AUTOSAR XML (schema 4-3-0)
package /MICROSAR/NvM_swc/DataTypes
  impl type NvM_RequestResultType: compu {0=NVM_REQ_OK, 1=NVM_REQ_NOT_OK, 2=NVM_REQ_PENDING, 3=NVM_REQ_INTEGRITY_FAILED, 4=NVM_REQ_BLOCK_SKIPPED, 5=NVM_REQ_NV_INVALIDATED, 6=NVM_REQ_CANCELED, 7=NVM_REQ_REDUNDANCY_FAILED, 8=NVM_REQ_RESTORED_FROM_ROM}, implementation-data-type=uint8
  impl type NvM_BlockIdType: range raw 1..32767, implementation-data-type=uint16
  impl type NvM_ServiceIdType: compu {6=NVM_READ_BLOCK, 7=NVM_WRITE_BLOCK, 8=NVM_RESTORE_BLOCK_DEFAULTS, 9=NVM_ERASE_BLOCK, 11=NVM_INVALIDATE_NV_BLOCK, 12=NVM_READ_ALL}, implementation-data-type=uint8
package /MICROSAR/NvM_swc/Interfaces
  6 x client server interface, all with is-service=true, service-kind=NON-VOLATILE-RAM-MANAGER:
    NvMAdministration
      operation SetBlockProtection: possible-error=NvMAdministration/E_NOT_OK
        arg ProtectionEnabled: type=boolean, direction=IN
      error E_NOT_OK: error-code=1
    NvMService_AC3_SRBS
      6 x operation, all with possible-error=NvMService_AC3_SRBS/E_NOT_OK:
        GetErrorStatus
          arg ErrorStatus: type=NvM_RequestResultType, direction=OUT
        SetRamBlockStatus
          arg RamBlockStatus: type=boolean, direction=IN
        ReadBlock
          arg DstPtr: type=dtRef_VOID, direction=IN
        WriteBlock
          arg SrcPtr: type=dtRef_const_VOID, direction=IN
        InvalidateNvBlock
        EraseBlock
      error E_NOT_OK: error-code=1
    NvMService_AC3_SRBS_Defs
      7 x operation, all with possible-error=NvMService_AC3_SRBS_Defs/E_NOT_OK:
        GetErrorStatus
          arg ErrorStatus: type=NvM_RequestResultType, direction=OUT
        SetRamBlockStatus
          arg RamBlockStatus: type=boolean, direction=IN
        ReadBlock
          arg DstPtr: type=dtRef_VOID, direction=IN
        WriteBlock
          arg SrcPtr: type=dtRef_const_VOID, direction=IN
        RestoreBlockDefaults
          arg DstPtr: type=dtRef_VOID, direction=IN
        InvalidateNvBlock
        EraseBlock
      error E_NOT_OK: error-code=1
    NvMNotifyJobFinished
      operation JobFinished
        arg ServiceId: type=NvM_ServiceIdType, direction=IN
        arg JobResult: type=NvM_RequestResultType, direction=IN
    NvMNotifyInitBlock
      operation InitBlock
    NvMService_AC3_SRBS_DS
      8 x operation, all with possible-error=NvMService_AC3_SRBS_DS/E_NOT_OK:
        GetErrorStatus
          arg ErrorStatus: type=NvM_RequestResultType, direction=OUT
        SetRamBlockStatus
          arg RamBlockStatus: type=boolean, direction=IN
        ReadBlock
          arg DstPtr: type=dtRef_VOID, direction=IN
        WriteBlock
          arg SrcPtr: type=dtRef_const_VOID, direction=IN
        SetDataIndex
          arg DataIndex: type=uint8, direction=IN
        GetDataIndex
          arg DataIndex: type=uint8, direction=OUT
        InvalidateNvBlock
        EraseBlock
      error E_NOT_OK: error-code=1
package /MICROSAR/NvM_swc/ComponentTypes
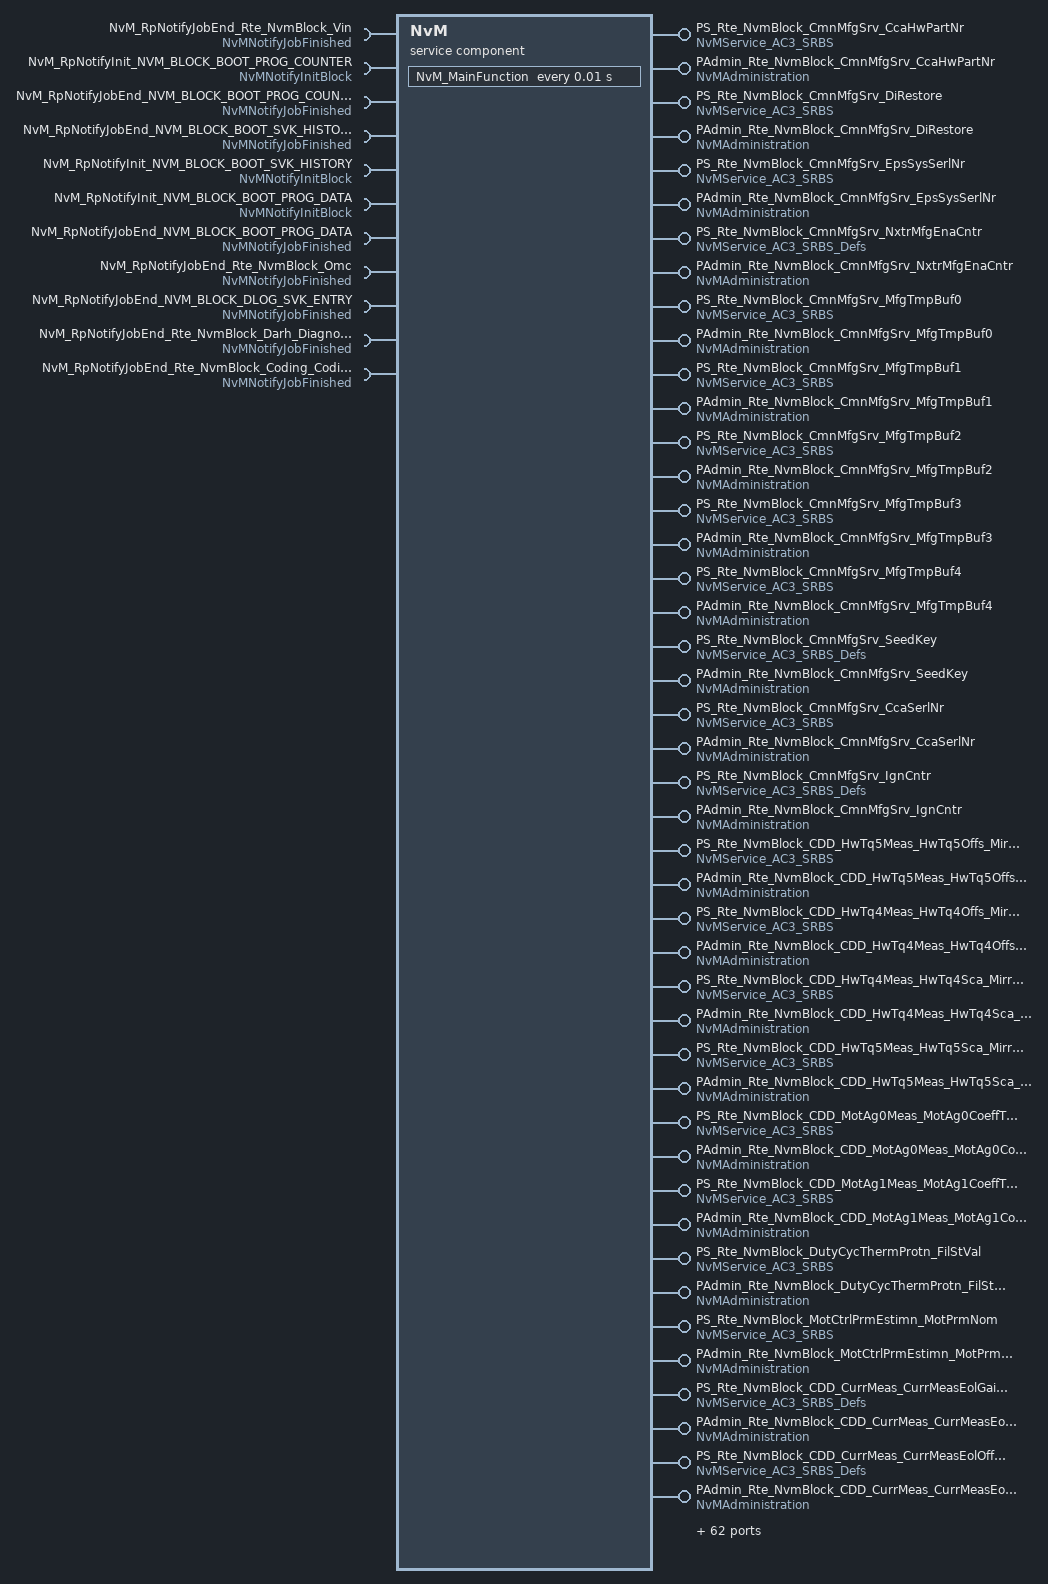
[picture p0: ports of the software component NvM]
  service sw component type NvM: category=SERVICE_COMPONENT
    62 x provide port:
      PS_Rte_NvmBlock_CmnMfgSrv_CcaHwPartNr: provided-interface=NvMService_AC3_SRBS
      PAdmin_Rte_NvmBlock_CmnMfgSrv_CcaHwPartNr: provided-interface=NvMAdministration
      PS_Rte_NvmBlock_CmnMfgSrv_DiRestore: provided-interface=NvMService_AC3_SRBS
      PAdmin_Rte_NvmBlock_CmnMfgSrv_DiRestore: provided-interface=NvMAdministration
      PS_Rte_NvmBlock_CmnMfgSrv_EpsSysSerlNr: provided-interface=NvMService_AC3_SRBS
      PAdmin_Rte_NvmBlock_CmnMfgSrv_EpsSysSerlNr: provided-interface=NvMAdministration
      PS_Rte_NvmBlock_CmnMfgSrv_NxtrMfgEnaCntr: provided-interface=NvMService_AC3_SRBS_Defs
      PAdmin_Rte_NvmBlock_CmnMfgSrv_NxtrMfgEnaCntr: provided-interface=NvMAdministration
      PS_Rte_NvmBlock_CmnMfgSrv_MfgTmpBuf0: provided-interface=NvMService_AC3_SRBS
      PAdmin_Rte_NvmBlock_CmnMfgSrv_MfgTmpBuf0: provided-interface=NvMAdministration
      PS_Rte_NvmBlock_CmnMfgSrv_MfgTmpBuf1: provided-interface=NvMService_AC3_SRBS
      PAdmin_Rte_NvmBlock_CmnMfgSrv_MfgTmpBuf1: provided-interface=NvMAdministration
      PS_Rte_NvmBlock_CmnMfgSrv_MfgTmpBuf2: provided-interface=NvMService_AC3_SRBS
      PAdmin_Rte_NvmBlock_CmnMfgSrv_MfgTmpBuf2: provided-interface=NvMAdministration
      PS_Rte_NvmBlock_CmnMfgSrv_MfgTmpBuf3: provided-interface=NvMService_AC3_SRBS
      PAdmin_Rte_NvmBlock_CmnMfgSrv_MfgTmpBuf3: provided-interface=NvMAdministration
      PS_Rte_NvmBlock_CmnMfgSrv_MfgTmpBuf4: provided-interface=NvMService_AC3_SRBS
      PAdmin_Rte_NvmBlock_CmnMfgSrv_MfgTmpBuf4: provided-interface=NvMAdministration
      PS_Rte_NvmBlock_CmnMfgSrv_SeedKey: provided-interface=NvMService_AC3_SRBS_Defs
      PAdmin_Rte_NvmBlock_CmnMfgSrv_SeedKey: provided-interface=NvMAdministration
      PS_Rte_NvmBlock_CmnMfgSrv_CcaSerlNr: provided-interface=NvMService_AC3_SRBS
      PAdmin_Rte_NvmBlock_CmnMfgSrv_CcaSerlNr: provided-interface=NvMAdministration
      PS_Rte_NvmBlock_CmnMfgSrv_IgnCntr: provided-interface=NvMService_AC3_SRBS_Defs
      PAdmin_Rte_NvmBlock_CmnMfgSrv_IgnCntr: provided-interface=NvMAdministration
      PS_Rte_NvmBlock_CDD_HwTq5Meas_HwTq5Offs_MirrorBlock: provided-interface=NvMService_AC3_SRBS
      PAdmin_Rte_NvmBlock_CDD_HwTq5Meas_HwTq5Offs_MirrorBlock: provided-interface=NvMAdministration
      PS_Rte_NvmBlock_CDD_HwTq4Meas_HwTq4Offs_MirrorBlock: provided-interface=NvMService_AC3_SRBS
      PAdmin_Rte_NvmBlock_CDD_HwTq4Meas_HwTq4Offs_MirrorBlock: provided-interface=NvMAdministration
      PS_Rte_NvmBlock_CDD_HwTq4Meas_HwTq4Sca_MirrorBlock: provided-interface=NvMService_AC3_SRBS
      PAdmin_Rte_NvmBlock_CDD_HwTq4Meas_HwTq4Sca_MirrorBlock: provided-interface=NvMAdministration
      PS_Rte_NvmBlock_CDD_HwTq5Meas_HwTq5Sca_MirrorBlock: provided-interface=NvMService_AC3_SRBS
      PAdmin_Rte_NvmBlock_CDD_HwTq5Meas_HwTq5Sca_MirrorBlock: provided-interface=NvMAdministration
      PS_Rte_NvmBlock_CDD_MotAg0Meas_MotAg0CoeffTbl: provided-interface=NvMService_AC3_SRBS
      PAdmin_Rte_NvmBlock_CDD_MotAg0Meas_MotAg0CoeffTbl: provided-interface=NvMAdministration
      PS_Rte_NvmBlock_CDD_MotAg1Meas_MotAg1CoeffTbl: provided-interface=NvMService_AC3_SRBS
      PAdmin_Rte_NvmBlock_CDD_MotAg1Meas_MotAg1CoeffTbl: provided-interface=NvMAdministration
      PS_Rte_NvmBlock_DutyCycThermProtn_FilStVal: provided-interface=NvMService_AC3_SRBS
      PAdmin_Rte_NvmBlock_DutyCycThermProtn_FilStVal: provided-interface=NvMAdministration
      PS_Rte_NvmBlock_MotCtrlPrmEstimn_MotPrmNom: provided-interface=NvMService_AC3_SRBS
      PAdmin_Rte_NvmBlock_MotCtrlPrmEstimn_MotPrmNom: provided-interface=NvMAdministration
      PS_Rte_NvmBlock_CDD_CurrMeas_CurrMeasEolGainCalSetABC: provided-interface=NvMService_AC3_SRBS_Defs
      PAdmin_Rte_NvmBlock_CDD_CurrMeas_CurrMeasEolGainCalSetABC: provided-interface=NvMAdministration
      PS_Rte_NvmBlock_CDD_CurrMeas_CurrMeasEolOffsCalSetABC: provided-interface=NvMService_AC3_SRBS_Defs
      PAdmin_Rte_NvmBlock_CDD_CurrMeas_CurrMeasEolOffsCalSetABC: provided-interface=NvMAdministration
      PS_Rte_NvmBlock_CDD_MotAgCmp_MotAgCmpMotAgBackEmf: provided-interface=NvMService_AC3_SRBS_Defs
      PAdmin_Rte_NvmBlock_CDD_MotAgCmp_MotAgCmpMotAgBackEmf: provided-interface=NvMAdministration
      PS_Rte_NvmBlock_HwTqCorrln_HwTqChACmnModCmpLpFilSt: provided-interface=NvMService_AC3_SRBS_Defs
      PAdmin_Rte_NvmBlock_HwTqCorrln_HwTqChACmnModCmpLpFilSt: provided-interface=NvMAdministration
      PS_Rte_NvmBlock_MotTqCmdSca_MotTqScaFac: provided-interface=NvMService_AC3_SRBS
      PAdmin_Rte_NvmBlock_MotTqCmdSca_MotTqScaFac: provided-interface=NvMAdministration
      PS_Rte_NvmBlock_PolarityCfg_PolarityCfgSaved: provided-interface=NvMService_AC3_SRBS_Defs
      PAdmin_Rte_NvmBlock_PolarityCfg_PolarityCfgSaved: provided-interface=NvMAdministration
      PS_Rte_NvmBlock_CDD_NvMProxy_ShtdwnClsChk: provided-interface=NvMService_AC3_SRBS
      PAdmin_Rte_NvmBlock_CDD_NvMProxy_ShtdwnClsChk: provided-interface=NvMAdministration
      PS_Rte_NvmBlock_DiagcMgr_DiagcMgrApplCrc: provided-interface=NvMService_AC3_SRBS_Defs
      PAdmin_Rte_NvmBlock_DiagcMgr_DiagcMgrApplCrc: provided-interface=NvMAdministration
      PS_Rte_NvmBlock_DiagcMgr_DiagcMgrLtchCntrAry: provided-interface=NvMService_AC3_SRBS
      PAdmin_Rte_NvmBlock_DiagcMgr_DiagcMgrLtchCntrAry: provided-interface=NvMAdministration
      PS_Rte_NvmBlock_DiagcMgr_DiagcMgrNtcFltAry: provided-interface=NvMService_AC3_SRBS
      PAdmin_Rte_NvmBlock_DiagcMgr_DiagcMgrNtcFltAry: provided-interface=NvMAdministration
      PS_Rte_NvmBlock_Vin: provided-interface=NvMService_AC3_SRBS_Defs
      PAdmin_Rte_NvmBlock_Vin: provided-interface=NvMAdministration
    require port NvM_RpNotifyJobEnd_Rte_NvmBlock_Vin: required-interface=NvMNotifyJobFinished
    4 x provide port:
      PS_Rte_NvmBlock_Omc: provided-interface=NvMService_AC3_SRBS_Defs
      PAdmin_Rte_NvmBlock_Omc: provided-interface=NvMAdministration
      PS_NVM_BLOCK_BOOT_PROG_COUNTER: provided-interface=NvMService_AC3_SRBS_Defs
      PAdmin_NVM_BLOCK_BOOT_PROG_COUNTER: provided-interface=NvMAdministration
    require port NvM_RpNotifyInit_NVM_BLOCK_BOOT_PROG_COUNTER: required-interface=NvMNotifyInitBlock
    10 x provide port:
      PS_NVM_BLOCK_BOOT_PROG_DATA: provided-interface=NvMService_AC3_SRBS_Defs
      PAdmin_NVM_BLOCK_BOOT_PROG_DATA: provided-interface=NvMAdministration
      PS_NVM_BLOCK_BOOT_SVK_HISTORY: provided-interface=NvMService_AC3_SRBS_Defs
      PAdmin_NVM_BLOCK_BOOT_SVK_HISTORY: provided-interface=NvMAdministration
      PS_NVM_BLOCK_DLOG_SVK_SYS_SUPP: provided-interface=NvMService_AC3_SRBS
      PAdmin_NVM_BLOCK_DLOG_SVK_SYS_SUPP: provided-interface=NvMAdministration
      PS_NVM_BLOCK_DLOG_SVK_PLANT: provided-interface=NvMService_AC3_SRBS
      PAdmin_NVM_BLOCK_DLOG_SVK_PLANT: provided-interface=NvMAdministration
      PAdmin_Rte_NvmBlock_Darh_ErrorQueue: provided-interface=NvMAdministration
      PS_Rte_NvmBlock_Darh_ErrorQueue: provided-interface=NvMService_AC3_SRBS
    require port NvM_RpNotifyJobEnd_NVM_BLOCK_BOOT_PROG_COUNTER: required-interface=NvMNotifyJobFinished
    12 x provide port:
      PS_Rte_NvmBlock_CDD_VrfyCritReg_MCalReadVrfyCritRegFltInfo: provided-interface=NvMService_AC3_SRBS
      PAdmin_Rte_NvmBlock_CDD_VrfyCritReg_MCalReadVrfyCritRegFltInfo: provided-interface=NvMAdministration
      PS_Rte_NvmBlock_BmwHwAgArbnAndEotPosn_BmwVehCentrOffs: provided-interface=NvMService_AC3_SRBS
      PAdmin_Rte_NvmBlock_BmwHwAgArbnAndEotPosn_BmwVehCentrOffs: provided-interface=NvMAdministration
      PS_Rte_NvmBlock_LrndRackCentr_LrndRackCentr: provided-interface=NvMService_AC3_SRBS
      PAdmin_Rte_NvmBlock_LrndRackCentr_LrndRackCentr: provided-interface=NvMAdministration
      PS_Rte_NvmBlock_ExcpnHndlg_McuDiagcData: provided-interface=NvMService_AC3_SRBS_Defs
      PAdmin_Rte_NvmBlock_ExcpnHndlg_McuDiagcData: provided-interface=NvMAdministration
      PS_Rte_NvmBlock_TEstimn_TFilStVal: provided-interface=NvMService_AC3_SRBS
      PAdmin_Rte_NvmBlock_TEstimn_TFilStVal: provided-interface=NvMAdministration
      PS_NVM_BLOCK_DLOG_SVK_ENTRY: provided-interface=NvMService_AC3_SRBS_DS
      PAdmin_NVM_BLOCK_DLOG_SVK_ENTRY: provided-interface=NvMAdministration
    4 x require port:
      NvM_RpNotifyJobEnd_NVM_BLOCK_BOOT_SVK_HISTORY: required-interface=NvMNotifyJobFinished
      NvM_RpNotifyInit_NVM_BLOCK_BOOT_SVK_HISTORY: required-interface=NvMNotifyInitBlock
      NvM_RpNotifyInit_NVM_BLOCK_BOOT_PROG_DATA: required-interface=NvMNotifyInitBlock
      NvM_RpNotifyJobEnd_NVM_BLOCK_BOOT_PROG_DATA: required-interface=NvMNotifyJobFinished
    provide port PS_Rte_NvmBlock_Darh_DiagnoseMasterEnable: provided-interface=NvMService_AC3_SRBS
    provide port PAdmin_Rte_NvmBlock_Darh_DiagnoseMasterEnable: provided-interface=NvMAdministration
    require port NvM_RpNotifyJobEnd_Rte_NvmBlock_Omc: required-interface=NvMNotifyJobFinished
    require port NvM_RpNotifyJobEnd_NVM_BLOCK_DLOG_SVK_ENTRY: required-interface=NvMNotifyJobFinished
    require port NvM_RpNotifyJobEnd_Rte_NvmBlock_Darh_DiagnoseMasterEnable: required-interface=NvMNotifyJobFinished
    4 x provide port:
      PS_Rte_NvmBlock_BmwTunSetHndlr_BmwDesIninIdx: provided-interface=NvMService_AC3_SRBS_Defs
      PAdmin_Rte_NvmBlock_BmwTunSetHndlr_BmwDesIninIdx: provided-interface=NvMAdministration
      PS_Rte_NvmBlock_Coding_CodingData: provided-interface=NvMService_AC3_SRBS_Defs
      PAdmin_Rte_NvmBlock_Coding_CodingData: provided-interface=NvMAdministration
    require port NvM_RpNotifyJobEnd_Rte_NvmBlock_Coding_CodingData: required-interface=NvMNotifyJobFinished
    12 x provide port:
      PS_Rte_NvmBlock_BmwTunSetHndlr_NvmBmwDesIninOptSetAIdx: provided-interface=NvMService_AC3_SRBS_Defs
      PAdmin_Rte_NvmBlock_BmwTunSetHndlr_NvmBmwDesIninOptSetAIdx: provided-interface=NvMAdministration
      PS_Rte_NvmBlock_BmwDiagcSrvHndlg_MilesKmEeprom: provided-interface=NvMService_AC3_SRBS
      PAdmin_Rte_NvmBlock_BmwDiagcSrvHndlg_MilesKmEeprom: provided-interface=NvMAdministration
      PS_Rte_NvmBlock_BmwDiagcSrvHndlg_ProgCntr: provided-interface=NvMService_AC3_SRBS
      PAdmin_Rte_NvmBlock_BmwDiagcSrvHndlg_ProgCntr: provided-interface=NvMAdministration
      PS_Rte_NvmBlock_BmwDiagcSrvHndlg_ProgCntrMaxVal: provided-interface=NvMService_AC3_SRBS_Defs
      PAdmin_Rte_NvmBlock_BmwDiagcSrvHndlg_ProgCntrMaxVal: provided-interface=NvMAdministration
      PS_Rte_NvmBlock_BmwDiagcSrvHndlg_TestStamp: provided-interface=NvMService_AC3_SRBS
      PAdmin_Rte_NvmBlock_BmwDiagcSrvHndlg_TestStamp: provided-interface=NvMAdministration
      PS_Rte_NvmBlock_PullCmpActv_PullCmpLongTerm: provided-interface=NvMService_AC3_SRBS_Defs
      PAdmin_Rte_NvmBlock_PullCmpActv_PullCmpLongTerm: provided-interface=NvMAdministration
    behavior NvMInternalBehavior: handle-termination-and-restart=NO-SUPPORT
      timing event Timer_NvM_MainFunction: start-on-event=NvM_MainFunction, period=0.01
      393 x operation invoked event:
        OpEventGetErrorStatus_GetErrorStatus_PS_Rte_NvmBlock_CmnMfgSrv_CcaHwPartNr: start-on-event=GetErrorStatus, operation=PS_Rte_NvmBlock_CmnMfgSrv_CcaHwPartNr.GetErrorStatus
        OpEventGetErrorStatus_GetErrorStatus_PS_Rte_NvmBlock_CmnMfgSrv_DiRestore: start-on-event=GetErrorStatus, operation=PS_Rte_NvmBlock_CmnMfgSrv_DiRestore.GetErrorStatus
        OpEventGetErrorStatus_GetErrorStatus_PS_Rte_NvmBlock_CmnMfgSrv_EpsSysSerlNr: start-on-event=GetErrorStatus, operation=PS_Rte_NvmBlock_CmnMfgSrv_EpsSysSerlNr.GetErrorStatus
        OpEventGetErrorStatus_GetErrorStatus_PS_Rte_NvmBlock_CmnMfgSrv_NxtrMfgEnaCntr: start-on-event=GetErrorStatus, operation=PS_Rte_NvmBlock_CmnMfgSrv_NxtrMfgEnaCntr.GetErrorStatus
        OpEventGetErrorStatus_GetErrorStatus_PS_Rte_NvmBlock_CmnMfgSrv_MfgTmpBuf{0..4}: start-on-event=GetErrorStatus, operation=PS_Rte_NvmBlock_CmnMfgSrv_MfgTmpBuf{0..4}.GetErrorStatus
        OpEventGetErrorStatus_GetErrorStatus_PS_Rte_NvmBlock_CmnMfgSrv_SeedKey: start-on-event=GetErrorStatus, operation=PS_Rte_NvmBlock_CmnMfgSrv_SeedKey.GetErrorStatus
        OpEventSetRamBlockStatus_SetRamBlockStatus_PS_Rte_NvmBlock_CmnMfgSrv_CcaHwPartNr: start-on-event=SetRamBlockStatus, operation=PS_Rte_NvmBlock_CmnMfgSrv_CcaHwPartNr.SetRamBlockStatus
        OpEventSetRamBlockStatus_SetRamBlockStatus_PS_Rte_NvmBlock_CmnMfgSrv_DiRestore: start-on-event=SetRamBlockStatus, operation=PS_Rte_NvmBlock_CmnMfgSrv_DiRestore.SetRamBlockStatus
        OpEventSetRamBlockStatus_SetRamBlockStatus_PS_Rte_NvmBlock_CmnMfgSrv_EpsSysSerlNr: start-on-event=SetRamBlockStatus, operation=PS_Rte_NvmBlock_CmnMfgSrv_EpsSysSerlNr.SetRamBlockStatus
        OpEventSetRamBlockStatus_SetRamBlockStatus_PS_Rte_NvmBlock_CmnMfgSrv_NxtrMfgEnaCntr: start-on-event=SetRamBlockStatus, operation=PS_Rte_NvmBlock_CmnMfgSrv_NxtrMfgEnaCntr.SetRamBlockStatus
        OpEventSetRamBlockStatus_SetRamBlockStatus_PS_Rte_NvmBlock_CmnMfgSrv_MfgTmpBuf{0..4}: start-on-event=SetRamBlockStatus, operation=PS_Rte_NvmBlock_CmnMfgSrv_MfgTmpBuf{0..4}.SetRamBlockStatus
        OpEventSetRamBlockStatus_SetRamBlockStatus_PS_Rte_NvmBlock_CmnMfgSrv_SeedKey: start-on-event=SetRamBlockStatus, operation=PS_Rte_NvmBlock_CmnMfgSrv_SeedKey.SetRamBlockStatus
        OpEventReadBlock_ReadBlock_PS_Rte_NvmBlock_CmnMfgSrv_CcaHwPartNr: start-on-event=ReadBlock, operation=PS_Rte_NvmBlock_CmnMfgSrv_CcaHwPartNr.ReadBlock
        OpEventReadBlock_ReadBlock_PS_Rte_NvmBlock_CmnMfgSrv_DiRestore: start-on-event=ReadBlock, operation=PS_Rte_NvmBlock_CmnMfgSrv_DiRestore.ReadBlock
        OpEventReadBlock_ReadBlock_PS_Rte_NvmBlock_CmnMfgSrv_EpsSysSerlNr: start-on-event=ReadBlock, operation=PS_Rte_NvmBlock_CmnMfgSrv_EpsSysSerlNr.ReadBlock
        OpEventReadBlock_ReadBlock_PS_Rte_NvmBlock_CmnMfgSrv_NxtrMfgEnaCntr: start-on-event=ReadBlock, operation=PS_Rte_NvmBlock_CmnMfgSrv_NxtrMfgEnaCntr.ReadBlock
        OpEventReadBlock_ReadBlock_PS_Rte_NvmBlock_CmnMfgSrv_MfgTmpBuf{0..4}: start-on-event=ReadBlock, operation=PS_Rte_NvmBlock_CmnMfgSrv_MfgTmpBuf{0..4}.ReadBlock
        OpEventReadBlock_ReadBlock_PS_Rte_NvmBlock_CmnMfgSrv_SeedKey: start-on-event=ReadBlock, operation=PS_Rte_NvmBlock_CmnMfgSrv_SeedKey.ReadBlock
        OpEventWriteBlock_WriteBlock_PS_Rte_NvmBlock_CmnMfgSrv_CcaHwPartNr: start-on-event=WriteBlock, operation=PS_Rte_NvmBlock_CmnMfgSrv_CcaHwPartNr.WriteBlock
        OpEventWriteBlock_WriteBlock_PS_Rte_NvmBlock_CmnMfgSrv_DiRestore: start-on-event=WriteBlock, operation=PS_Rte_NvmBlock_CmnMfgSrv_DiRestore.WriteBlock
        OpEventWriteBlock_WriteBlock_PS_Rte_NvmBlock_CmnMfgSrv_EpsSysSerlNr: start-on-event=WriteBlock, operation=PS_Rte_NvmBlock_CmnMfgSrv_EpsSysSerlNr.WriteBlock
        OpEventWriteBlock_WriteBlock_PS_Rte_NvmBlock_CmnMfgSrv_NxtrMfgEnaCntr: start-on-event=WriteBlock, operation=PS_Rte_NvmBlock_CmnMfgSrv_NxtrMfgEnaCntr.WriteBlock
        OpEventWriteBlock_WriteBlock_PS_Rte_NvmBlock_CmnMfgSrv_MfgTmpBuf{0..4}: start-on-event=WriteBlock, operation=PS_Rte_NvmBlock_CmnMfgSrv_MfgTmpBuf{0..4}.WriteBlock
        OpEventWriteBlock_WriteBlock_PS_Rte_NvmBlock_CmnMfgSrv_SeedKey: start-on-event=WriteBlock, operation=PS_Rte_NvmBlock_CmnMfgSrv_SeedKey.WriteBlock
        OpEventInvalidateNvBlock_InvalidateNvBlock_PS_Rte_NvmBlock_CmnMfgSrv_CcaHwPartNr: start-on-event=InvalidateNvBlock, operation=PS_Rte_NvmBlock_CmnMfgSrv_CcaHwPartNr.InvalidateNvBlock
        OpEventInvalidateNvBlock_InvalidateNvBlock_PS_Rte_NvmBlock_CmnMfgSrv_DiRestore: start-on-event=InvalidateNvBlock, operation=PS_Rte_NvmBlock_CmnMfgSrv_DiRestore.InvalidateNvBlock
        OpEventInvalidateNvBlock_InvalidateNvBlock_PS_Rte_NvmBlock_CmnMfgSrv_EpsSysSerlNr: start-on-event=InvalidateNvBlock, operation=PS_Rte_NvmBlock_CmnMfgSrv_EpsSysSerlNr.InvalidateNvBlock
        OpEventInvalidateNvBlock_InvalidateNvBlock_PS_Rte_NvmBlock_CmnMfgSrv_NxtrMfgEnaCntr: start-on-event=InvalidateNvBlock, operation=PS_Rte_NvmBlock_CmnMfgSrv_NxtrMfgEnaCntr.InvalidateNvBlock
        OpEventInvalidateNvBlock_InvalidateNvBlock_PS_Rte_NvmBlock_CmnMfgSrv_MfgTmpBuf{0..4}: start-on-event=InvalidateNvBlock, operation=PS_Rte_NvmBlock_CmnMfgSrv_MfgTmpBuf{0..4}.InvalidateNvBlock
        OpEventInvalidateNvBlock_InvalidateNvBlock_PS_Rte_NvmBlock_CmnMfgSrv_SeedKey: start-on-event=InvalidateNvBlock, operation=PS_Rte_NvmBlock_CmnMfgSrv_SeedKey.InvalidateNvBlock
        OpEventEraseBlock_EraseBlock_PS_Rte_NvmBlock_CmnMfgSrv_CcaHwPartNr: start-on-event=EraseBlock, operation=PS_Rte_NvmBlock_CmnMfgSrv_CcaHwPartNr.EraseBlock
        OpEventEraseBlock_EraseBlock_PS_Rte_NvmBlock_CmnMfgSrv_DiRestore: start-on-event=EraseBlock, operation=PS_Rte_NvmBlock_CmnMfgSrv_DiRestore.EraseBlock
        OpEventEraseBlock_EraseBlock_PS_Rte_NvmBlock_CmnMfgSrv_EpsSysSerlNr: start-on-event=EraseBlock, operation=PS_Rte_NvmBlock_CmnMfgSrv_EpsSysSerlNr.EraseBlock
        OpEventEraseBlock_EraseBlock_PS_Rte_NvmBlock_CmnMfgSrv_NxtrMfgEnaCntr: start-on-event=EraseBlock, operation=PS_Rte_NvmBlock_CmnMfgSrv_NxtrMfgEnaCntr.EraseBlock
        OpEventEraseBlock_EraseBlock_PS_Rte_NvmBlock_CmnMfgSrv_MfgTmpBuf{0..4}: start-on-event=EraseBlock, operation=PS_Rte_NvmBlock_CmnMfgSrv_MfgTmpBuf{0..4}.EraseBlock
        OpEventEraseBlock_EraseBlock_PS_Rte_NvmBlock_CmnMfgSrv_SeedKey: start-on-event=EraseBlock, operation=PS_Rte_NvmBlock_CmnMfgSrv_SeedKey.EraseBlock
        OpEventSetBlockProtection_SetBlockProtection_PAdmin_Rte_NvmBlock_CmnMfgSrv_CcaHwPartNr: start-on-event=SetBlockProtection, operation=PAdmin_Rte_NvmBlock_CmnMfgSrv_CcaHwPartNr.SetBlockProtection
        OpEventSetBlockProtection_SetBlockProtection_PAdmin_Rte_NvmBlock_CmnMfgSrv_DiRestore: start-on-event=SetBlockProtection, operation=PAdmin_Rte_NvmBlock_CmnMfgSrv_DiRestore.SetBlockProtection
        OpEventSetBlockProtection_SetBlockProtection_PAdmin_Rte_NvmBlock_CmnMfgSrv_EpsSysSerlNr: start-on-event=SetBlockProtection, operation=PAdmin_Rte_NvmBlock_CmnMfgSrv_EpsSysSerlNr.SetBlockProtection
        OpEventSetBlockProtection_SetBlockProtection_PAdmin_Rte_NvmBlock_CmnMfgSrv_NxtrMfgEnaCntr: start-on-event=SetBlockProtection, operation=PAdmin_Rte_NvmBlock_CmnMfgSrv_NxtrMfgEnaCntr.SetBlockProtection
        OpEventSetBlockProtection_SetBlockProtection_PAdmin_Rte_NvmBlock_CmnMfgSrv_MfgTmpBuf{0..4}: start-on-event=SetBlockProtection, operation=PAdmin_Rte_NvmBlock_CmnMfgSrv_MfgTmpBuf{0..4}.SetBlockProtection
        OpEventSetBlockProtection_SetBlockProtection_PAdmin_Rte_NvmBlock_CmnMfgSrv_SeedKey: start-on-event=SetBlockProtection, operation=PAdmin_Rte_NvmBlock_CmnMfgSrv_SeedKey.SetBlockProtection
        OpEventRestoreBlockDefaults_RestoreBlockDefaults_PS_Rte_NvmBlock_CmnMfgSrv_NxtrMfgEnaCntr: start-on-event=RestoreBlockDefaults, operation=PS_Rte_NvmBlock_CmnMfgSrv_NxtrMfgEnaCntr.RestoreBlockDefaults
        OpEventRestoreBlockDefaults_RestoreBlockDefaults_PS_Rte_NvmBlock_CmnMfgSrv_SeedKey: start-on-event=RestoreBlockDefaults, operation=PS_Rte_NvmBlock_CmnMfgSrv_SeedKey.RestoreBlockDefaults
        OpEventGetErrorStatus_GetErrorStatus_PS_Rte_NvmBlock_CmnMfgSrv_CcaSerlNr: start-on-event=GetErrorStatus, operation=PS_Rte_NvmBlock_CmnMfgSrv_CcaSerlNr.GetErrorStatus
        OpEventSetRamBlockStatus_SetRamBlockStatus_PS_Rte_NvmBlock_CmnMfgSrv_CcaSerlNr: start-on-event=SetRamBlockStatus, operation=PS_Rte_NvmBlock_CmnMfgSrv_CcaSerlNr.SetRamBlockStatus
        OpEventReadBlock_ReadBlock_PS_Rte_NvmBlock_CmnMfgSrv_CcaSerlNr: start-on-event=ReadBlock, operation=PS_Rte_NvmBlock_CmnMfgSrv_CcaSerlNr.ReadBlock
        OpEventWriteBlock_WriteBlock_PS_Rte_NvmBlock_CmnMfgSrv_CcaSerlNr: start-on-event=WriteBlock, operation=PS_Rte_NvmBlock_CmnMfgSrv_CcaSerlNr.WriteBlock
        OpEventInvalidateNvBlock_InvalidateNvBlock_PS_Rte_NvmBlock_CmnMfgSrv_CcaSerlNr: start-on-event=InvalidateNvBlock, operation=PS_Rte_NvmBlock_CmnMfgSrv_CcaSerlNr.InvalidateNvBlock
        OpEventEraseBlock_EraseBlock_PS_Rte_NvmBlock_CmnMfgSrv_CcaSerlNr: start-on-event=EraseBlock, operation=PS_Rte_NvmBlock_CmnMfgSrv_CcaSerlNr.EraseBlock
        OpEventSetBlockProtection_SetBlockProtection_PAdmin_Rte_NvmBlock_CmnMfgSrv_CcaSerlNr: start-on-event=SetBlockProtection, operation=PAdmin_Rte_NvmBlock_CmnMfgSrv_CcaSerlNr.SetBlockProtection
        OpEventGetErrorStatus_GetErrorStatus_PS_Rte_NvmBlock_CmnMfgSrv_IgnCntr: start-on-event=GetErrorStatus, operation=PS_Rte_NvmBlock_CmnMfgSrv_IgnCntr.GetErrorStatus
        OpEventSetRamBlockStatus_SetRamBlockStatus_PS_Rte_NvmBlock_CmnMfgSrv_IgnCntr: start-on-event=SetRamBlockStatus, operation=PS_Rte_NvmBlock_CmnMfgSrv_IgnCntr.SetRamBlockStatus
        OpEventReadBlock_ReadBlock_PS_Rte_NvmBlock_CmnMfgSrv_IgnCntr: start-on-event=ReadBlock, operation=PS_Rte_NvmBlock_CmnMfgSrv_IgnCntr.ReadBlock
        OpEventWriteBlock_WriteBlock_PS_Rte_NvmBlock_CmnMfgSrv_IgnCntr: start-on-event=WriteBlock, operation=PS_Rte_NvmBlock_CmnMfgSrv_IgnCntr.WriteBlock
        OpEventInvalidateNvBlock_InvalidateNvBlock_PS_Rte_NvmBlock_CmnMfgSrv_IgnCntr: start-on-event=InvalidateNvBlock, operation=PS_Rte_NvmBlock_CmnMfgSrv_IgnCntr.InvalidateNvBlock
        OpEventEraseBlock_EraseBlock_PS_Rte_NvmBlock_CmnMfgSrv_IgnCntr: start-on-event=EraseBlock, operation=PS_Rte_NvmBlock_CmnMfgSrv_IgnCntr.EraseBlock
        OpEventSetBlockProtection_SetBlockProtection_PAdmin_Rte_NvmBlock_CmnMfgSrv_IgnCntr: start-on-event=SetBlockProtection, operation=PAdmin_Rte_NvmBlock_CmnMfgSrv_IgnCntr.SetBlockProtection
        OpEventRestoreBlockDefaults_RestoreBlockDefaults_PS_Rte_NvmBlock_CmnMfgSrv_IgnCntr: start-on-event=RestoreBlockDefaults, operation=PS_Rte_NvmBlock_CmnMfgSrv_IgnCntr.RestoreBlockDefaults
        OpEventGetErrorStatus_GetErrorStatus_PS_Rte_NvmBlock_CDD_HwTq5Meas_HwTq5Offs_MirrorBlock: start-on-event=GetErrorStatus, operation=PS_Rte_NvmBlock_CDD_HwTq5Meas_HwTq5Offs_MirrorBlock.GetErrorStatus
        OpEventGetErrorStatus_GetErrorStatus_PS_Rte_NvmBlock_CDD_HwTq4Meas_HwTq4Offs_MirrorBlock: start-on-event=GetErrorStatus, operation=PS_Rte_NvmBlock_CDD_HwTq4Meas_HwTq4Offs_MirrorBlock.GetErrorStatus
        OpEventGetErrorStatus_GetErrorStatus_PS_Rte_NvmBlock_CDD_HwTq4Meas_HwTq4Sca_MirrorBlock: start-on-event=GetErrorStatus, operation=PS_Rte_NvmBlock_CDD_HwTq4Meas_HwTq4Sca_MirrorBlock.GetErrorStatus
        OpEventGetErrorStatus_GetErrorStatus_PS_Rte_NvmBlock_CDD_HwTq5Meas_HwTq5Sca_MirrorBlock: start-on-event=GetErrorStatus, operation=PS_Rte_NvmBlock_CDD_HwTq5Meas_HwTq5Sca_MirrorBlock.GetErrorStatus
        OpEventGetErrorStatus_GetErrorStatus_PS_Rte_NvmBlock_CDD_MotAg0Meas_MotAg0CoeffTbl: start-on-event=GetErrorStatus, operation=PS_Rte_NvmBlock_CDD_MotAg0Meas_MotAg0CoeffTbl.GetErrorStatus
        OpEventGetErrorStatus_GetErrorStatus_PS_Rte_NvmBlock_CDD_MotAg1Meas_MotAg1CoeffTbl: start-on-event=GetErrorStatus, operation=PS_Rte_NvmBlock_CDD_MotAg1Meas_MotAg1CoeffTbl.GetErrorStatus
        OpEventSetRamBlockStatus_SetRamBlockStatus_PS_Rte_NvmBlock_CDD_HwTq5Meas_HwTq5Offs_MirrorBlock: start-on-event=SetRamBlockStatus, operation=PS_Rte_NvmBlock_CDD_HwTq5Meas_HwTq5Offs_MirrorBlock.SetRamBlockStatus
        OpEventSetRamBlockStatus_SetRamBlockStatus_PS_Rte_NvmBlock_CDD_HwTq4Meas_HwTq4Offs_MirrorBlock: start-on-event=SetRamBlockStatus, operation=PS_Rte_NvmBlock_CDD_HwTq4Meas_HwTq4Offs_MirrorBlock.SetRamBlockStatus
        OpEventSetRamBlockStatus_SetRamBlockStatus_PS_Rte_NvmBlock_CDD_HwTq4Meas_HwTq4Sca_MirrorBlock: start-on-event=SetRamBlockStatus, operation=PS_Rte_NvmBlock_CDD_HwTq4Meas_HwTq4Sca_MirrorBlock.SetRamBlockStatus
        OpEventSetRamBlockStatus_SetRamBlockStatus_PS_Rte_NvmBlock_CDD_HwTq5Meas_HwTq5Sca_MirrorBlock: start-on-event=SetRamBlockStatus, operation=PS_Rte_NvmBlock_CDD_HwTq5Meas_HwTq5Sca_MirrorBlock.SetRamBlockStatus
        OpEventSetRamBlockStatus_SetRamBlockStatus_PS_Rte_NvmBlock_CDD_MotAg0Meas_MotAg0CoeffTbl: start-on-event=SetRamBlockStatus, operation=PS_Rte_NvmBlock_CDD_MotAg0Meas_MotAg0CoeffTbl.SetRamBlockStatus
        OpEventSetRamBlockStatus_SetRamBlockStatus_PS_Rte_NvmBlock_CDD_MotAg1Meas_MotAg1CoeffTbl: start-on-event=SetRamBlockStatus, operation=PS_Rte_NvmBlock_CDD_MotAg1Meas_MotAg1CoeffTbl.SetRamBlockStatus
        OpEventReadBlock_ReadBlock_PS_Rte_NvmBlock_CDD_HwTq5Meas_HwTq5Offs_MirrorBlock: start-on-event=ReadBlock, operation=PS_Rte_NvmBlock_CDD_HwTq5Meas_HwTq5Offs_MirrorBlock.ReadBlock
        OpEventReadBlock_ReadBlock_PS_Rte_NvmBlock_CDD_HwTq4Meas_HwTq4Offs_MirrorBlock: start-on-event=ReadBlock, operation=PS_Rte_NvmBlock_CDD_HwTq4Meas_HwTq4Offs_MirrorBlock.ReadBlock
        OpEventReadBlock_ReadBlock_PS_Rte_NvmBlock_CDD_HwTq4Meas_HwTq4Sca_MirrorBlock: start-on-event=ReadBlock, operation=PS_Rte_NvmBlock_CDD_HwTq4Meas_HwTq4Sca_MirrorBlock.ReadBlock
        OpEventReadBlock_ReadBlock_PS_Rte_NvmBlock_CDD_HwTq5Meas_HwTq5Sca_MirrorBlock: start-on-event=ReadBlock, operation=PS_Rte_NvmBlock_CDD_HwTq5Meas_HwTq5Sca_MirrorBlock.ReadBlock
        OpEventReadBlock_ReadBlock_PS_Rte_NvmBlock_CDD_MotAg0Meas_MotAg0CoeffTbl: start-on-event=ReadBlock, operation=PS_Rte_NvmBlock_CDD_MotAg0Meas_MotAg0CoeffTbl.ReadBlock
        OpEventReadBlock_ReadBlock_PS_Rte_NvmBlock_CDD_MotAg1Meas_MotAg1CoeffTbl: start-on-event=ReadBlock, operation=PS_Rte_NvmBlock_CDD_MotAg1Meas_MotAg1CoeffTbl.ReadBlock
        OpEventWriteBlock_WriteBlock_PS_Rte_NvmBlock_CDD_HwTq5Meas_HwTq5Offs_MirrorBlock: start-on-event=WriteBlock, operation=PS_Rte_NvmBlock_CDD_HwTq5Meas_HwTq5Offs_MirrorBlock.WriteBlock
        OpEventWriteBlock_WriteBlock_PS_Rte_NvmBlock_CDD_HwTq4Meas_HwTq4Offs_MirrorBlock: start-on-event=WriteBlock, operation=PS_Rte_NvmBlock_CDD_HwTq4Meas_HwTq4Offs_MirrorBlock.WriteBlock
        OpEventWriteBlock_WriteBlock_PS_Rte_NvmBlock_CDD_HwTq4Meas_HwTq4Sca_MirrorBlock: start-on-event=WriteBlock, operation=PS_Rte_NvmBlock_CDD_HwTq4Meas_HwTq4Sca_MirrorBlock.WriteBlock
        OpEventWriteBlock_WriteBlock_PS_Rte_NvmBlock_CDD_HwTq5Meas_HwTq5Sca_MirrorBlock: start-on-event=WriteBlock, operation=PS_Rte_NvmBlock_CDD_HwTq5Meas_HwTq5Sca_MirrorBlock.WriteBlock
        OpEventWriteBlock_WriteBlock_PS_Rte_NvmBlock_CDD_MotAg0Meas_MotAg0CoeffTbl: start-on-event=WriteBlock, operation=PS_Rte_NvmBlock_CDD_MotAg0Meas_MotAg0CoeffTbl.WriteBlock
        OpEventWriteBlock_WriteBlock_PS_Rte_NvmBlock_CDD_MotAg1Meas_MotAg1CoeffTbl: start-on-event=WriteBlock, operation=PS_Rte_NvmBlock_CDD_MotAg1Meas_MotAg1CoeffTbl.WriteBlock
        OpEventInvalidateNvBlock_InvalidateNvBlock_PS_Rte_NvmBlock_CDD_HwTq5Meas_HwTq5Offs_MirrorBlock: start-on-event=InvalidateNvBlock, operation=PS_Rte_NvmBlock_CDD_HwTq5Meas_HwTq5Offs_MirrorBlock.InvalidateNvBlock
        OpEventInvalidateNvBlock_InvalidateNvBlock_PS_Rte_NvmBlock_CDD_HwTq4Meas_HwTq4Offs_MirrorBlock: start-on-event=InvalidateNvBlock, operation=PS_Rte_NvmBlock_CDD_HwTq4Meas_HwTq4Offs_MirrorBlock.InvalidateNvBlock
        OpEventInvalidateNvBlock_InvalidateNvBlock_PS_Rte_NvmBlock_CDD_HwTq4Meas_HwTq4Sca_MirrorBlock: start-on-event=InvalidateNvBlock, operation=PS_Rte_NvmBlock_CDD_HwTq4Meas_HwTq4Sca_MirrorBlock.InvalidateNvBlock
        OpEventInvalidateNvBlock_InvalidateNvBlock_PS_Rte_NvmBlock_CDD_HwTq5Meas_HwTq5Sca_MirrorBlock: start-on-event=InvalidateNvBlock, operation=PS_Rte_NvmBlock_CDD_HwTq5Meas_HwTq5Sca_MirrorBlock.InvalidateNvBlock
        OpEventInvalidateNvBlock_InvalidateNvBlock_PS_Rte_NvmBlock_CDD_MotAg0Meas_MotAg0CoeffTbl: start-on-event=InvalidateNvBlock, operation=PS_Rte_NvmBlock_CDD_MotAg0Meas_MotAg0CoeffTbl.InvalidateNvBlock
        OpEventInvalidateNvBlock_InvalidateNvBlock_PS_Rte_NvmBlock_CDD_MotAg1Meas_MotAg1CoeffTbl: start-on-event=InvalidateNvBlock, operation=PS_Rte_NvmBlock_CDD_MotAg1Meas_MotAg1CoeffTbl.InvalidateNvBlock
        OpEventEraseBlock_EraseBlock_PS_Rte_NvmBlock_CDD_HwTq5Meas_HwTq5Offs_MirrorBlock: start-on-event=EraseBlock, operation=PS_Rte_NvmBlock_CDD_HwTq5Meas_HwTq5Offs_MirrorBlock.EraseBlock
        OpEventEraseBlock_EraseBlock_PS_Rte_NvmBlock_CDD_HwTq4Meas_HwTq4Offs_MirrorBlock: start-on-event=EraseBlock, operation=PS_Rte_NvmBlock_CDD_HwTq4Meas_HwTq4Offs_MirrorBlock.EraseBlock
        OpEventEraseBlock_EraseBlock_PS_Rte_NvmBlock_CDD_HwTq4Meas_HwTq4Sca_MirrorBlock: start-on-event=EraseBlock, operation=PS_Rte_NvmBlock_CDD_HwTq4Meas_HwTq4Sca_MirrorBlock.EraseBlock
        OpEventEraseBlock_EraseBlock_PS_Rte_NvmBlock_CDD_HwTq5Meas_HwTq5Sca_MirrorBlock: start-on-event=EraseBlock, operation=PS_Rte_NvmBlock_CDD_HwTq5Meas_HwTq5Sca_MirrorBlock.EraseBlock
        OpEventEraseBlock_EraseBlock_PS_Rte_NvmBlock_CDD_MotAg0Meas_MotAg0CoeffTbl: start-on-event=EraseBlock, operation=PS_Rte_NvmBlock_CDD_MotAg0Meas_MotAg0CoeffTbl.EraseBlock
        OpEventEraseBlock_EraseBlock_PS_Rte_NvmBlock_CDD_MotAg1Meas_MotAg1CoeffTbl: start-on-event=EraseBlock, operation=PS_Rte_NvmBlock_CDD_MotAg1Meas_MotAg1CoeffTbl.EraseBlock
        OpEventSetBlockProtection_SetBlockProtection_PAdmin_Rte_NvmBlock_CDD_HwTq5Meas_HwTq5Offs_MirrorBlock: start-on-event=SetBlockProtection, operation=PAdmin_Rte_NvmBlock_CDD_HwTq5Meas_HwTq5Offs_MirrorBlock.SetBlockProtection
        OpEventSetBlockProtection_SetBlockProtection_PAdmin_Rte_NvmBlock_CDD_HwTq4Meas_HwTq4Offs_MirrorBlock: start-on-event=SetBlockProtection, operation=PAdmin_Rte_NvmBlock_CDD_HwTq4Meas_HwTq4Offs_MirrorBlock.SetBlockProtection
        OpEventSetBlockProtection_SetBlockProtection_PAdmin_Rte_NvmBlock_CDD_HwTq4Meas_HwTq4Sca_MirrorBlock: start-on-event=SetBlockProtection, operation=PAdmin_Rte_NvmBlock_CDD_HwTq4Meas_HwTq4Sca_MirrorBlock.SetBlockProtection
        OpEventSetBlockProtection_SetBlockProtection_PAdmin_Rte_NvmBlock_CDD_HwTq5Meas_HwTq5Sca_MirrorBlock: start-on-event=SetBlockProtection, operation=PAdmin_Rte_NvmBlock_CDD_HwTq5Meas_HwTq5Sca_MirrorBlock.SetBlockProtection
        OpEventSetBlockProtection_SetBlockProtection_PAdmin_Rte_NvmBlock_CDD_MotAg0Meas_MotAg0CoeffTbl: start-on-event=SetBlockProtection, operation=PAdmin_Rte_NvmBlock_CDD_MotAg0Meas_MotAg0CoeffTbl.SetBlockProtection
        OpEventSetBlockProtection_SetBlockProtection_PAdmin_Rte_NvmBlock_CDD_MotAg1Meas_MotAg1CoeffTbl: start-on-event=SetBlockProtection, operation=PAdmin_Rte_NvmBlock_CDD_MotAg1Meas_MotAg1CoeffTbl.SetBlockProtection
        OpEventGetErrorStatus_GetErrorStatus_PS_Rte_NvmBlock_DutyCycThermProtn_FilStVal: start-on-event=GetErrorStatus, operation=PS_Rte_NvmBlock_DutyCycThermProtn_FilStVal.GetErrorStatus
        OpEventSetRamBlockStatus_SetRamBlockStatus_PS_Rte_NvmBlock_DutyCycThermProtn_FilStVal: start-on-event=SetRamBlockStatus, operation=PS_Rte_NvmBlock_DutyCycThermProtn_FilStVal.SetRamBlockStatus
        OpEventReadBlock_ReadBlock_PS_Rte_NvmBlock_DutyCycThermProtn_FilStVal: start-on-event=ReadBlock, operation=PS_Rte_NvmBlock_DutyCycThermProtn_FilStVal.ReadBlock
        OpEventWriteBlock_WriteBlock_PS_Rte_NvmBlock_DutyCycThermProtn_FilStVal: start-on-event=WriteBlock, operation=PS_Rte_NvmBlock_DutyCycThermProtn_FilStVal.WriteBlock
        OpEventInvalidateNvBlock_InvalidateNvBlock_PS_Rte_NvmBlock_DutyCycThermProtn_FilStVal: start-on-event=InvalidateNvBlock, operation=PS_Rte_NvmBlock_DutyCycThermProtn_FilStVal.InvalidateNvBlock
        OpEventEraseBlock_EraseBlock_PS_Rte_NvmBlock_DutyCycThermProtn_FilStVal: start-on-event=EraseBlock, operation=PS_Rte_NvmBlock_DutyCycThermProtn_FilStVal.EraseBlock
        OpEventSetBlockProtection_SetBlockProtection_PAdmin_Rte_NvmBlock_DutyCycThermProtn_FilStVal: start-on-event=SetBlockProtection, operation=PAdmin_Rte_NvmBlock_DutyCycThermProtn_FilStVal.SetBlockProtection
        OpEventGetErrorStatus_GetErrorStatus_PS_Rte_NvmBlock_MotCtrlPrmEstimn_MotPrmNom: start-on-event=GetErrorStatus, operation=PS_Rte_NvmBlock_MotCtrlPrmEstimn_MotPrmNom.GetErrorStatus
        OpEventSetRamBlockStatus_SetRamBlockStatus_PS_Rte_NvmBlock_MotCtrlPrmEstimn_MotPrmNom: start-on-event=SetRamBlockStatus, operation=PS_Rte_NvmBlock_MotCtrlPrmEstimn_MotPrmNom.SetRamBlockStatus
        OpEventReadBlock_ReadBlock_PS_Rte_NvmBlock_MotCtrlPrmEstimn_MotPrmNom: start-on-event=ReadBlock, operation=PS_Rte_NvmBlock_MotCtrlPrmEstimn_MotPrmNom.ReadBlock
        OpEventWriteBlock_WriteBlock_PS_Rte_NvmBlock_MotCtrlPrmEstimn_MotPrmNom: start-on-event=WriteBlock, operation=PS_Rte_NvmBlock_MotCtrlPrmEstimn_MotPrmNom.WriteBlock
        OpEventInvalidateNvBlock_InvalidateNvBlock_PS_Rte_NvmBlock_MotCtrlPrmEstimn_MotPrmNom: start-on-event=InvalidateNvBlock, operation=PS_Rte_NvmBlock_MotCtrlPrmEstimn_MotPrmNom.InvalidateNvBlock
        OpEventEraseBlock_EraseBlock_PS_Rte_NvmBlock_MotCtrlPrmEstimn_MotPrmNom: start-on-event=EraseBlock, operation=PS_Rte_NvmBlock_MotCtrlPrmEstimn_MotPrmNom.EraseBlock
        OpEventSetBlockProtection_SetBlockProtection_PAdmin_Rte_NvmBlock_MotCtrlPrmEstimn_MotPrmNom: start-on-event=SetBlockProtection, operation=PAdmin_Rte_NvmBlock_MotCtrlPrmEstimn_MotPrmNom.SetBlockProtection
        OpEventGetErrorStatus_GetErrorStatus_PS_Rte_NvmBlock_CDD_CurrMeas_CurrMeasEolGainCalSetABC: start-on-event=GetErrorStatus, operation=PS_Rte_NvmBlock_CDD_CurrMeas_CurrMeasEolGainCalSetABC.GetErrorStatus
        OpEventGetErrorStatus_GetErrorStatus_PS_Rte_NvmBlock_CDD_CurrMeas_CurrMeasEolOffsCalSetABC: start-on-event=GetErrorStatus, operation=PS_Rte_NvmBlock_CDD_CurrMeas_CurrMeasEolOffsCalSetABC.GetErrorStatus
        OpEventSetRamBlockStatus_SetRamBlockStatus_PS_Rte_NvmBlock_CDD_CurrMeas_CurrMeasEolGainCalSetABC: start-on-event=SetRamBlockStatus, operation=PS_Rte_NvmBlock_CDD_CurrMeas_CurrMeasEolGainCalSetABC.SetRamBlockStatus
        OpEventSetRamBlockStatus_SetRamBlockStatus_PS_Rte_NvmBlock_CDD_CurrMeas_CurrMeasEolOffsCalSetABC: start-on-event=SetRamBlockStatus, operation=PS_Rte_NvmBlock_CDD_CurrMeas_CurrMeasEolOffsCalSetABC.SetRamBlockStatus
        OpEventReadBlock_ReadBlock_PS_Rte_NvmBlock_CDD_CurrMeas_CurrMeasEolGainCalSetABC: start-on-event=ReadBlock, operation=PS_Rte_NvmBlock_CDD_CurrMeas_CurrMeasEolGainCalSetABC.ReadBlock
        OpEventReadBlock_ReadBlock_PS_Rte_NvmBlock_CDD_CurrMeas_CurrMeasEolOffsCalSetABC: start-on-event=ReadBlock, operation=PS_Rte_NvmBlock_CDD_CurrMeas_CurrMeasEolOffsCalSetABC.ReadBlock
        OpEventWriteBlock_WriteBlock_PS_Rte_NvmBlock_CDD_CurrMeas_CurrMeasEolGainCalSetABC: start-on-event=WriteBlock, operation=PS_Rte_NvmBlock_CDD_CurrMeas_CurrMeasEolGainCalSetABC.WriteBlock
        OpEventWriteBlock_WriteBlock_PS_Rte_NvmBlock_CDD_CurrMeas_CurrMeasEolOffsCalSetABC: start-on-event=WriteBlock, operation=PS_Rte_NvmBlock_CDD_CurrMeas_CurrMeasEolOffsCalSetABC.WriteBlock
        OpEventRestoreBlockDefaults_RestoreBlockDefaults_PS_Rte_NvmBlock_CDD_CurrMeas_CurrMeasEolGainCalSetABC: start-on-event=RestoreBlockDefaults, operation=PS_Rte_NvmBlock_CDD_CurrMeas_CurrMeasEolGainCalSetABC.RestoreBlockDefaults
        OpEventRestoreBlockDefaults_RestoreBlockDefaults_PS_Rte_NvmBlock_CDD_CurrMeas_CurrMeasEolOffsCalSetABC: start-on-event=RestoreBlockDefaults, operation=PS_Rte_NvmBlock_CDD_CurrMeas_CurrMeasEolOffsCalSetABC.RestoreBlockDefaults
        OpEventInvalidateNvBlock_InvalidateNvBlock_PS_Rte_NvmBlock_CDD_CurrMeas_CurrMeasEolGainCalSetABC: start-on-event=InvalidateNvBlock, operation=PS_Rte_NvmBlock_CDD_CurrMeas_CurrMeasEolGainCalSetABC.InvalidateNvBlock
        OpEventInvalidateNvBlock_InvalidateNvBlock_PS_Rte_NvmBlock_CDD_CurrMeas_CurrMeasEolOffsCalSetABC: start-on-event=InvalidateNvBlock, operation=PS_Rte_NvmBlock_CDD_CurrMeas_CurrMeasEolOffsCalSetABC.InvalidateNvBlock
        OpEventEraseBlock_EraseBlock_PS_Rte_NvmBlock_CDD_CurrMeas_CurrMeasEolGainCalSetABC: start-on-event=EraseBlock, operation=PS_Rte_NvmBlock_CDD_CurrMeas_CurrMeasEolGainCalSetABC.EraseBlock
        OpEventEraseBlock_EraseBlock_PS_Rte_NvmBlock_CDD_CurrMeas_CurrMeasEolOffsCalSetABC: start-on-event=EraseBlock, operation=PS_Rte_NvmBlock_CDD_CurrMeas_CurrMeasEolOffsCalSetABC.EraseBlock
        OpEventSetBlockProtection_SetBlockProtection_PAdmin_Rte_NvmBlock_CDD_CurrMeas_CurrMeasEolGainCalSetABC: start-on-event=SetBlockProtection, operation=PAdmin_Rte_NvmBlock_CDD_CurrMeas_CurrMeasEolGainCalSetABC.SetBlockProtection
        OpEventSetBlockProtection_SetBlockProtection_PAdmin_Rte_NvmBlock_CDD_CurrMeas_CurrMeasEolOffsCalSetABC: start-on-event=SetBlockProtection, operation=PAdmin_Rte_NvmBlock_CDD_CurrMeas_CurrMeasEolOffsCalSetABC.SetBlockProtection
        OpEventGetErrorStatus_GetErrorStatus_PS_Rte_NvmBlock_CDD_MotAgCmp_MotAgCmpMotAgBackEmf: start-on-event=GetErrorStatus, operation=PS_Rte_NvmBlock_CDD_MotAgCmp_MotAgCmpMotAgBackEmf.GetErrorStatus
        OpEventGetErrorStatus_GetErrorStatus_PS_Rte_NvmBlock_HwTqCorrln_HwTqChACmnModCmpLpFilSt: start-on-event=GetErrorStatus, operation=PS_Rte_NvmBlock_HwTqCorrln_HwTqChACmnModCmpLpFilSt.GetErrorStatus
        OpEventGetErrorStatus_GetErrorStatus_PS_Rte_NvmBlock_MotTqCmdSca_MotTqScaFac: start-on-event=GetErrorStatus, operation=PS_Rte_NvmBlock_MotTqCmdSca_MotTqScaFac.GetErrorStatus
        OpEventGetErrorStatus_GetErrorStatus_PS_Rte_NvmBlock_PolarityCfg_PolarityCfgSaved: start-on-event=GetErrorStatus, operation=PS_Rte_NvmBlock_PolarityCfg_PolarityCfgSaved.GetErrorStatus
        OpEventGetErrorStatus_GetErrorStatus_PS_Rte_NvmBlock_CDD_NvMProxy_ShtdwnClsChk: start-on-event=GetErrorStatus, operation=PS_Rte_NvmBlock_CDD_NvMProxy_ShtdwnClsChk.GetErrorStatus
        OpEventGetErrorStatus_GetErrorStatus_PS_Rte_NvmBlock_DiagcMgr_DiagcMgrApplCrc: start-on-event=GetErrorStatus, operation=PS_Rte_NvmBlock_DiagcMgr_DiagcMgrApplCrc.GetErrorStatus
        OpEventGetErrorStatus_GetErrorStatus_PS_Rte_NvmBlock_DiagcMgr_DiagcMgrLtchCntrAry: start-on-event=GetErrorStatus, operation=PS_Rte_NvmBlock_DiagcMgr_DiagcMgrLtchCntrAry.GetErrorStatus
        OpEventGetErrorStatus_GetErrorStatus_PS_Rte_NvmBlock_DiagcMgr_DiagcMgrNtcFltAry: start-on-event=GetErrorStatus, operation=PS_Rte_NvmBlock_DiagcMgr_DiagcMgrNtcFltAry.GetErrorStatus
        OpEventSetRamBlockStatus_SetRamBlockStatus_PS_Rte_NvmBlock_CDD_MotAgCmp_MotAgCmpMotAgBackEmf: start-on-event=SetRamBlockStatus, operation=PS_Rte_NvmBlock_CDD_MotAgCmp_MotAgCmpMotAgBackEmf.SetRamBlockStatus
        OpEventSetRamBlockStatus_SetRamBlockStatus_PS_Rte_NvmBlock_HwTqCorrln_HwTqChACmnModCmpLpFilSt: start-on-event=SetRamBlockStatus, operation=PS_Rte_NvmBlock_HwTqCorrln_HwTqChACmnModCmpLpFilSt.SetRamBlockStatus
        OpEventSetRamBlockStatus_SetRamBlockStatus_PS_Rte_NvmBlock_MotTqCmdSca_MotTqScaFac: start-on-event=SetRamBlockStatus, operation=PS_Rte_NvmBlock_MotTqCmdSca_MotTqScaFac.SetRamBlockStatus
        OpEventSetRamBlockStatus_SetRamBlockStatus_PS_Rte_NvmBlock_PolarityCfg_PolarityCfgSaved: start-on-event=SetRamBlockStatus, operation=PS_Rte_NvmBlock_PolarityCfg_PolarityCfgSaved.SetRamBlockStatus
        OpEventSetRamBlockStatus_SetRamBlockStatus_PS_Rte_NvmBlock_CDD_NvMProxy_ShtdwnClsChk: start-on-event=SetRamBlockStatus, operation=PS_Rte_NvmBlock_CDD_NvMProxy_ShtdwnClsChk.SetRamBlockStatus
        OpEventSetRamBlockStatus_SetRamBlockStatus_PS_Rte_NvmBlock_DiagcMgr_DiagcMgrApplCrc: start-on-event=SetRamBlockStatus, operation=PS_Rte_NvmBlock_DiagcMgr_DiagcMgrApplCrc.SetRamBlockStatus
        OpEventSetRamBlockStatus_SetRamBlockStatus_PS_Rte_NvmBlock_DiagcMgr_DiagcMgrLtchCntrAry: start-on-event=SetRamBlockStatus, operation=PS_Rte_NvmBlock_DiagcMgr_DiagcMgrLtchCntrAry.SetRamBlockStatus
        OpEventSetRamBlockStatus_SetRamBlockStatus_PS_Rte_NvmBlock_DiagcMgr_DiagcMgrNtcFltAry: start-on-event=SetRamBlockStatus, operation=PS_Rte_NvmBlock_DiagcMgr_DiagcMgrNtcFltAry.SetRamBlockStatus
        OpEventReadBlock_ReadBlock_PS_Rte_NvmBlock_CDD_MotAgCmp_MotAgCmpMotAgBackEmf: start-on-event=ReadBlock, operation=PS_Rte_NvmBlock_CDD_MotAgCmp_MotAgCmpMotAgBackEmf.ReadBlock
        OpEventReadBlock_ReadBlock_PS_Rte_NvmBlock_HwTqCorrln_HwTqChACmnModCmpLpFilSt: start-on-event=ReadBlock, operation=PS_Rte_NvmBlock_HwTqCorrln_HwTqChACmnModCmpLpFilSt.ReadBlock
        OpEventReadBlock_ReadBlock_PS_Rte_NvmBlock_MotTqCmdSca_MotTqScaFac: start-on-event=ReadBlock, operation=PS_Rte_NvmBlock_MotTqCmdSca_MotTqScaFac.ReadBlock
        OpEventReadBlock_ReadBlock_PS_Rte_NvmBlock_PolarityCfg_PolarityCfgSaved: start-on-event=ReadBlock, operation=PS_Rte_NvmBlock_PolarityCfg_PolarityCfgSaved.ReadBlock
        OpEventReadBlock_ReadBlock_PS_Rte_NvmBlock_CDD_NvMProxy_ShtdwnClsChk: start-on-event=ReadBlock, operation=PS_Rte_NvmBlock_CDD_NvMProxy_ShtdwnClsChk.ReadBlock
        OpEventReadBlock_ReadBlock_PS_Rte_NvmBlock_DiagcMgr_DiagcMgrApplCrc: start-on-event=ReadBlock, operation=PS_Rte_NvmBlock_DiagcMgr_DiagcMgrApplCrc.ReadBlock
        OpEventReadBlock_ReadBlock_PS_Rte_NvmBlock_DiagcMgr_DiagcMgrLtchCntrAry: start-on-event=ReadBlock, operation=PS_Rte_NvmBlock_DiagcMgr_DiagcMgrLtchCntrAry.ReadBlock
        OpEventReadBlock_ReadBlock_PS_Rte_NvmBlock_DiagcMgr_DiagcMgrNtcFltAry: start-on-event=ReadBlock, operation=PS_Rte_NvmBlock_DiagcMgr_DiagcMgrNtcFltAry.ReadBlock
        OpEventWriteBlock_WriteBlock_PS_Rte_NvmBlock_CDD_MotAgCmp_MotAgCmpMotAgBackEmf: start-on-event=WriteBlock, operation=PS_Rte_NvmBlock_CDD_MotAgCmp_MotAgCmpMotAgBackEmf.WriteBlock
        OpEventWriteBlock_WriteBlock_PS_Rte_NvmBlock_HwTqCorrln_HwTqChACmnModCmpLpFilSt: start-on-event=WriteBlock, operation=PS_Rte_NvmBlock_HwTqCorrln_HwTqChACmnModCmpLpFilSt.WriteBlock
        OpEventWriteBlock_WriteBlock_PS_Rte_NvmBlock_MotTqCmdSca_MotTqScaFac: start-on-event=WriteBlock, operation=PS_Rte_NvmBlock_MotTqCmdSca_MotTqScaFac.WriteBlock
        OpEventWriteBlock_WriteBlock_PS_Rte_NvmBlock_PolarityCfg_PolarityCfgSaved: start-on-event=WriteBlock, operation=PS_Rte_NvmBlock_PolarityCfg_PolarityCfgSaved.WriteBlock
        OpEventWriteBlock_WriteBlock_PS_Rte_NvmBlock_CDD_NvMProxy_ShtdwnClsChk: start-on-event=WriteBlock, operation=PS_Rte_NvmBlock_CDD_NvMProxy_ShtdwnClsChk.WriteBlock
        OpEventWriteBlock_WriteBlock_PS_Rte_NvmBlock_DiagcMgr_DiagcMgrApplCrc: start-on-event=WriteBlock, operation=PS_Rte_NvmBlock_DiagcMgr_DiagcMgrApplCrc.WriteBlock
        OpEventWriteBlock_WriteBlock_PS_Rte_NvmBlock_DiagcMgr_DiagcMgrLtchCntrAry: start-on-event=WriteBlock, operation=PS_Rte_NvmBlock_DiagcMgr_DiagcMgrLtchCntrAry.WriteBlock
        OpEventWriteBlock_WriteBlock_PS_Rte_NvmBlock_DiagcMgr_DiagcMgrNtcFltAry: start-on-event=WriteBlock, operation=PS_Rte_NvmBlock_DiagcMgr_DiagcMgrNtcFltAry.WriteBlock
        OpEventInvalidateNvBlock_InvalidateNvBlock_PS_Rte_NvmBlock_CDD_MotAgCmp_MotAgCmpMotAgBackEmf: start-on-event=InvalidateNvBlock, operation=PS_Rte_NvmBlock_CDD_MotAgCmp_MotAgCmpMotAgBackEmf.InvalidateNvBlock
        OpEventInvalidateNvBlock_InvalidateNvBlock_PS_Rte_NvmBlock_HwTqCorrln_HwTqChACmnModCmpLpFilSt: start-on-event=InvalidateNvBlock, operation=PS_Rte_NvmBlock_HwTqCorrln_HwTqChACmnModCmpLpFilSt.InvalidateNvBlock
        OpEventInvalidateNvBlock_InvalidateNvBlock_PS_Rte_NvmBlock_MotTqCmdSca_MotTqScaFac: start-on-event=InvalidateNvBlock, operation=PS_Rte_NvmBlock_MotTqCmdSca_MotTqScaFac.InvalidateNvBlock
        OpEventInvalidateNvBlock_InvalidateNvBlock_PS_Rte_NvmBlock_PolarityCfg_PolarityCfgSaved: start-on-event=InvalidateNvBlock, operation=PS_Rte_NvmBlock_PolarityCfg_PolarityCfgSaved.InvalidateNvBlock
        OpEventInvalidateNvBlock_InvalidateNvBlock_PS_Rte_NvmBlock_CDD_NvMProxy_ShtdwnClsChk: start-on-event=InvalidateNvBlock, operation=PS_Rte_NvmBlock_CDD_NvMProxy_ShtdwnClsChk.InvalidateNvBlock
        OpEventInvalidateNvBlock_InvalidateNvBlock_PS_Rte_NvmBlock_DiagcMgr_DiagcMgrApplCrc: start-on-event=InvalidateNvBlock, operation=PS_Rte_NvmBlock_DiagcMgr_DiagcMgrApplCrc.InvalidateNvBlock
        OpEventInvalidateNvBlock_InvalidateNvBlock_PS_Rte_NvmBlock_DiagcMgr_DiagcMgrLtchCntrAry: start-on-event=InvalidateNvBlock, operation=PS_Rte_NvmBlock_DiagcMgr_DiagcMgrLtchCntrAry.InvalidateNvBlock
        OpEventInvalidateNvBlock_InvalidateNvBlock_PS_Rte_NvmBlock_DiagcMgr_DiagcMgrNtcFltAry: start-on-event=InvalidateNvBlock, operation=PS_Rte_NvmBlock_DiagcMgr_DiagcMgrNtcFltAry.InvalidateNvBlock
        OpEventEraseBlock_EraseBlock_PS_Rte_NvmBlock_CDD_MotAgCmp_MotAgCmpMotAgBackEmf: start-on-event=EraseBlock, operation=PS_Rte_NvmBlock_CDD_MotAgCmp_MotAgCmpMotAgBackEmf.EraseBlock
        OpEventEraseBlock_EraseBlock_PS_Rte_NvmBlock_HwTqCorrln_HwTqChACmnModCmpLpFilSt: start-on-event=EraseBlock, operation=PS_Rte_NvmBlock_HwTqCorrln_HwTqChACmnModCmpLpFilSt.EraseBlock
        OpEventEraseBlock_EraseBlock_PS_Rte_NvmBlock_MotTqCmdSca_MotTqScaFac: start-on-event=EraseBlock, operation=PS_Rte_NvmBlock_MotTqCmdSca_MotTqScaFac.EraseBlock
        OpEventEraseBlock_EraseBlock_PS_Rte_NvmBlock_PolarityCfg_PolarityCfgSaved: start-on-event=EraseBlock, operation=PS_Rte_NvmBlock_PolarityCfg_PolarityCfgSaved.EraseBlock
        OpEventEraseBlock_EraseBlock_PS_Rte_NvmBlock_CDD_NvMProxy_ShtdwnClsChk: start-on-event=EraseBlock, operation=PS_Rte_NvmBlock_CDD_NvMProxy_ShtdwnClsChk.EraseBlock
        OpEventEraseBlock_EraseBlock_PS_Rte_NvmBlock_DiagcMgr_DiagcMgrApplCrc: start-on-event=EraseBlock, operation=PS_Rte_NvmBlock_DiagcMgr_DiagcMgrApplCrc.EraseBlock
        OpEventEraseBlock_EraseBlock_PS_Rte_NvmBlock_DiagcMgr_DiagcMgrLtchCntrAry: start-on-event=EraseBlock, operation=PS_Rte_NvmBlock_DiagcMgr_DiagcMgrLtchCntrAry.EraseBlock
        OpEventEraseBlock_EraseBlock_PS_Rte_NvmBlock_DiagcMgr_DiagcMgrNtcFltAry: start-on-event=EraseBlock, operation=PS_Rte_NvmBlock_DiagcMgr_DiagcMgrNtcFltAry.EraseBlock
        OpEventSetBlockProtection_SetBlockProtection_PAdmin_Rte_NvmBlock_CDD_MotAgCmp_MotAgCmpMotAgBackEmf: start-on-event=SetBlockProtection, operation=PAdmin_Rte_NvmBlock_CDD_MotAgCmp_MotAgCmpMotAgBackEmf.SetBlockProtection
        OpEventSetBlockProtection_SetBlockProtection_PAdmin_Rte_NvmBlock_HwTqCorrln_HwTqChACmnModCmpLpFilSt: start-on-event=SetBlockProtection, operation=PAdmin_Rte_NvmBlock_HwTqCorrln_HwTqChACmnModCmpLpFilSt.SetBlockProtection
        OpEventSetBlockProtection_SetBlockProtection_PAdmin_Rte_NvmBlock_MotTqCmdSca_MotTqScaFac: start-on-event=SetBlockProtection, operation=PAdmin_Rte_NvmBlock_MotTqCmdSca_MotTqScaFac.SetBlockProtection
        OpEventSetBlockProtection_SetBlockProtection_PAdmin_Rte_NvmBlock_PolarityCfg_PolarityCfgSaved: start-on-event=SetBlockProtection, operation=PAdmin_Rte_NvmBlock_PolarityCfg_PolarityCfgSaved.SetBlockProtection
        OpEventSetBlockProtection_SetBlockProtection_PAdmin_Rte_NvmBlock_CDD_NvMProxy_ShtdwnClsChk: start-on-event=SetBlockProtection, operation=PAdmin_Rte_NvmBlock_CDD_NvMProxy_ShtdwnClsChk.SetBlockProtection
        OpEventSetBlockProtection_SetBlockProtection_PAdmin_Rte_NvmBlock_DiagcMgr_DiagcMgrApplCrc: start-on-event=SetBlockProtection, operation=PAdmin_Rte_NvmBlock_DiagcMgr_DiagcMgrApplCrc.SetBlockProtection
        OpEventSetBlockProtection_SetBlockProtection_PAdmin_Rte_NvmBlock_DiagcMgr_DiagcMgrLtchCntrAry: start-on-event=SetBlockProtection, operation=PAdmin_Rte_NvmBlock_DiagcMgr_DiagcMgrLtchCntrAry.SetBlockProtection
        OpEventSetBlockProtection_SetBlockProtection_PAdmin_Rte_NvmBlock_DiagcMgr_DiagcMgrNtcFltAry: start-on-event=SetBlockProtection, operation=PAdmin_Rte_NvmBlock_DiagcMgr_DiagcMgrNtcFltAry.SetBlockProtection
        OpEventRestoreBlockDefaults_RestoreBlockDefaults_PS_Rte_NvmBlock_CDD_MotAgCmp_MotAgCmpMotAgBackEmf: start-on-event=RestoreBlockDefaults, operation=PS_Rte_NvmBlock_CDD_MotAgCmp_MotAgCmpMotAgBackEmf.RestoreBlockDefaults
        OpEventRestoreBlockDefaults_RestoreBlockDefaults_PS_Rte_NvmBlock_HwTqCorrln_HwTqChACmnModCmpLpFilSt: start-on-event=RestoreBlockDefaults, operation=PS_Rte_NvmBlock_HwTqCorrln_HwTqChACmnModCmpLpFilSt.RestoreBlockDefaults
        OpEventRestoreBlockDefaults_RestoreBlockDefaults_PS_Rte_NvmBlock_PolarityCfg_PolarityCfgSaved: start-on-event=RestoreBlockDefaults, operation=PS_Rte_NvmBlock_PolarityCfg_PolarityCfgSaved.RestoreBlockDefaults
        OpEventRestoreBlockDefaults_RestoreBlockDefaults_PS_Rte_NvmBlock_DiagcMgr_DiagcMgrApplCrc: start-on-event=RestoreBlockDefaults, operation=PS_Rte_NvmBlock_DiagcMgr_DiagcMgrApplCrc.RestoreBlockDefaults
        OpEventGetErrorStatus_GetErrorStatus_PS_Rte_NvmBlock_Vin: start-on-event=GetErrorStatus, operation=PS_Rte_NvmBlock_Vin.GetErrorStatus
        OpEventGetErrorStatus_GetErrorStatus_PS_Rte_NvmBlock_Omc: start-on-event=GetErrorStatus, operation=PS_Rte_NvmBlock_Omc.GetErrorStatus
        OpEventGetErrorStatus_GetErrorStatus_PS_NVM_BLOCK_BOOT_PROG_COUNTER: start-on-event=GetErrorStatus, operation=PS_NVM_BLOCK_BOOT_PROG_COUNTER.GetErrorStatus
        OpEventSetRamBlockStatus_SetRamBlockStatus_PS_Rte_NvmBlock_Vin: start-on-event=SetRamBlockStatus, operation=PS_Rte_NvmBlock_Vin.SetRamBlockStatus
        OpEventSetRamBlockStatus_SetRamBlockStatus_PS_Rte_NvmBlock_Omc: start-on-event=SetRamBlockStatus, operation=PS_Rte_NvmBlock_Omc.SetRamBlockStatus
        OpEventSetRamBlockStatus_SetRamBlockStatus_PS_NVM_BLOCK_BOOT_PROG_COUNTER: start-on-event=SetRamBlockStatus, operation=PS_NVM_BLOCK_BOOT_PROG_COUNTER.SetRamBlockStatus
        OpEventReadBlock_ReadBlock_PS_Rte_NvmBlock_Vin: start-on-event=ReadBlock, operation=PS_Rte_NvmBlock_Vin.ReadBlock
        OpEventReadBlock_ReadBlock_PS_Rte_NvmBlock_Omc: start-on-event=ReadBlock, operation=PS_Rte_NvmBlock_Omc.ReadBlock
        OpEventReadBlock_ReadBlock_PS_NVM_BLOCK_BOOT_PROG_COUNTER: start-on-event=ReadBlock, operation=PS_NVM_BLOCK_BOOT_PROG_COUNTER.ReadBlock
        OpEventWriteBlock_WriteBlock_PS_Rte_NvmBlock_Vin: start-on-event=WriteBlock, operation=PS_Rte_NvmBlock_Vin.WriteBlock
        OpEventWriteBlock_WriteBlock_PS_Rte_NvmBlock_Omc: start-on-event=WriteBlock, operation=PS_Rte_NvmBlock_Omc.WriteBlock
        OpEventWriteBlock_WriteBlock_PS_NVM_BLOCK_BOOT_PROG_COUNTER: start-on-event=WriteBlock, operation=PS_NVM_BLOCK_BOOT_PROG_COUNTER.WriteBlock
        OpEventInvalidateNvBlock_InvalidateNvBlock_PS_Rte_NvmBlock_Vin: start-on-event=InvalidateNvBlock, operation=PS_Rte_NvmBlock_Vin.InvalidateNvBlock
        OpEventInvalidateNvBlock_InvalidateNvBlock_PS_Rte_NvmBlock_Omc: start-on-event=InvalidateNvBlock, operation=PS_Rte_NvmBlock_Omc.InvalidateNvBlock
        OpEventInvalidateNvBlock_InvalidateNvBlock_PS_NVM_BLOCK_BOOT_PROG_COUNTER: start-on-event=InvalidateNvBlock, operation=PS_NVM_BLOCK_BOOT_PROG_COUNTER.InvalidateNvBlock
        OpEventEraseBlock_EraseBlock_PS_Rte_NvmBlock_Vin: start-on-event=EraseBlock, operation=PS_Rte_NvmBlock_Vin.EraseBlock
        OpEventEraseBlock_EraseBlock_PS_Rte_NvmBlock_Omc: start-on-event=EraseBlock, operation=PS_Rte_NvmBlock_Omc.EraseBlock
        OpEventEraseBlock_EraseBlock_PS_NVM_BLOCK_BOOT_PROG_COUNTER: start-on-event=EraseBlock, operation=PS_NVM_BLOCK_BOOT_PROG_COUNTER.EraseBlock
        OpEventSetBlockProtection_SetBlockProtection_PAdmin_Rte_NvmBlock_Vin: start-on-event=SetBlockProtection, operation=PAdmin_Rte_NvmBlock_Vin.SetBlockProtection
        OpEventSetBlockProtection_SetBlockProtection_PAdmin_Rte_NvmBlock_Omc: start-on-event=SetBlockProtection, operation=PAdmin_Rte_NvmBlock_Omc.SetBlockProtection
        OpEventSetBlockProtection_SetBlockProtection_PAdmin_NVM_BLOCK_BOOT_PROG_COUNTER: start-on-event=SetBlockProtection, operation=PAdmin_NVM_BLOCK_BOOT_PROG_COUNTER.SetBlockProtection
        OpEventRestoreBlockDefaults_RestoreBlockDefaults_PS_Rte_NvmBlock_Vin: start-on-event=RestoreBlockDefaults, operation=PS_Rte_NvmBlock_Vin.RestoreBlockDefaults
        OpEventRestoreBlockDefaults_RestoreBlockDefaults_PS_Rte_NvmBlock_Omc: start-on-event=RestoreBlockDefaults, operation=PS_Rte_NvmBlock_Omc.RestoreBlockDefaults
        OpEventRestoreBlockDefaults_RestoreBlockDefaults_PS_NVM_BLOCK_BOOT_PROG_COUNTER: start-on-event=RestoreBlockDefaults, operation=PS_NVM_BLOCK_BOOT_PROG_COUNTER.RestoreBlockDefaults
        OpEventGetErrorStatus_GetErrorStatus_PS_NVM_BLOCK_BOOT_PROG_DATA: start-on-event=GetErrorStatus, operation=PS_NVM_BLOCK_BOOT_PROG_DATA.GetErrorStatus
        OpEventGetErrorStatus_GetErrorStatus_PS_NVM_BLOCK_BOOT_SVK_HISTORY: start-on-event=GetErrorStatus, operation=PS_NVM_BLOCK_BOOT_SVK_HISTORY.GetErrorStatus
        OpEventSetRamBlockStatus_SetRamBlockStatus_PS_NVM_BLOCK_BOOT_PROG_DATA: start-on-event=SetRamBlockStatus, operation=PS_NVM_BLOCK_BOOT_PROG_DATA.SetRamBlockStatus
        OpEventSetRamBlockStatus_SetRamBlockStatus_PS_NVM_BLOCK_BOOT_SVK_HISTORY: start-on-event=SetRamBlockStatus, operation=PS_NVM_BLOCK_BOOT_SVK_HISTORY.SetRamBlockStatus
        OpEventReadBlock_ReadBlock_PS_NVM_BLOCK_BOOT_PROG_DATA: start-on-event=ReadBlock, operation=PS_NVM_BLOCK_BOOT_PROG_DATA.ReadBlock
        OpEventReadBlock_ReadBlock_PS_NVM_BLOCK_BOOT_SVK_HISTORY: start-on-event=ReadBlock, operation=PS_NVM_BLOCK_BOOT_SVK_HISTORY.ReadBlock
        OpEventWriteBlock_WriteBlock_PS_NVM_BLOCK_BOOT_PROG_DATA: start-on-event=WriteBlock, operation=PS_NVM_BLOCK_BOOT_PROG_DATA.WriteBlock
        OpEventWriteBlock_WriteBlock_PS_NVM_BLOCK_BOOT_SVK_HISTORY: start-on-event=WriteBlock, operation=PS_NVM_BLOCK_BOOT_SVK_HISTORY.WriteBlock
        OpEventInvalidateNvBlock_InvalidateNvBlock_PS_NVM_BLOCK_BOOT_PROG_DATA: start-on-event=InvalidateNvBlock, operation=PS_NVM_BLOCK_BOOT_PROG_DATA.InvalidateNvBlock
        OpEventInvalidateNvBlock_InvalidateNvBlock_PS_NVM_BLOCK_BOOT_SVK_HISTORY: start-on-event=InvalidateNvBlock, operation=PS_NVM_BLOCK_BOOT_SVK_HISTORY.InvalidateNvBlock
        OpEventEraseBlock_EraseBlock_PS_NVM_BLOCK_BOOT_PROG_DATA: start-on-event=EraseBlock, operation=PS_NVM_BLOCK_BOOT_PROG_DATA.EraseBlock
        OpEventEraseBlock_EraseBlock_PS_NVM_BLOCK_BOOT_SVK_HISTORY: start-on-event=EraseBlock, operation=PS_NVM_BLOCK_BOOT_SVK_HISTORY.EraseBlock
        OpEventSetBlockProtection_SetBlockProtection_PAdmin_NVM_BLOCK_BOOT_PROG_DATA: start-on-event=SetBlockProtection, operation=PAdmin_NVM_BLOCK_BOOT_PROG_DATA.SetBlockProtection
        OpEventSetBlockProtection_SetBlockProtection_PAdmin_NVM_BLOCK_BOOT_SVK_HISTORY: start-on-event=SetBlockProtection, operation=PAdmin_NVM_BLOCK_BOOT_SVK_HISTORY.SetBlockProtection
        OpEventGetErrorStatus_GetErrorStatus_PS_NVM_BLOCK_DLOG_SVK_SYS_SUPP: start-on-event=GetErrorStatus, operation=PS_NVM_BLOCK_DLOG_SVK_SYS_SUPP.GetErrorStatus
        OpEventGetErrorStatus_GetErrorStatus_PS_NVM_BLOCK_DLOG_SVK_PLANT: start-on-event=GetErrorStatus, operation=PS_NVM_BLOCK_DLOG_SVK_PLANT.GetErrorStatus
        OpEventSetRamBlockStatus_SetRamBlockStatus_PS_NVM_BLOCK_DLOG_SVK_SYS_SUPP: start-on-event=SetRamBlockStatus, operation=PS_NVM_BLOCK_DLOG_SVK_SYS_SUPP.SetRamBlockStatus
        OpEventSetRamBlockStatus_SetRamBlockStatus_PS_NVM_BLOCK_DLOG_SVK_PLANT: start-on-event=SetRamBlockStatus, operation=PS_NVM_BLOCK_DLOG_SVK_PLANT.SetRamBlockStatus
        OpEventReadBlock_ReadBlock_PS_NVM_BLOCK_DLOG_SVK_SYS_SUPP: start-on-event=ReadBlock, operation=PS_NVM_BLOCK_DLOG_SVK_SYS_SUPP.ReadBlock
        OpEventReadBlock_ReadBlock_PS_NVM_BLOCK_DLOG_SVK_PLANT: start-on-event=ReadBlock, operation=PS_NVM_BLOCK_DLOG_SVK_PLANT.ReadBlock
        OpEventWriteBlock_WriteBlock_PS_NVM_BLOCK_DLOG_SVK_SYS_SUPP: start-on-event=WriteBlock, operation=PS_NVM_BLOCK_DLOG_SVK_SYS_SUPP.WriteBlock
        OpEventWriteBlock_WriteBlock_PS_NVM_BLOCK_DLOG_SVK_PLANT: start-on-event=WriteBlock, operation=PS_NVM_BLOCK_DLOG_SVK_PLANT.WriteBlock
        OpEventInvalidateNvBlock_InvalidateNvBlock_PS_NVM_BLOCK_DLOG_SVK_SYS_SUPP: start-on-event=InvalidateNvBlock, operation=PS_NVM_BLOCK_DLOG_SVK_SYS_SUPP.InvalidateNvBlock
        OpEventInvalidateNvBlock_InvalidateNvBlock_PS_NVM_BLOCK_DLOG_SVK_PLANT: start-on-event=InvalidateNvBlock, operation=PS_NVM_BLOCK_DLOG_SVK_PLANT.InvalidateNvBlock
        OpEventEraseBlock_EraseBlock_PS_NVM_BLOCK_DLOG_SVK_SYS_SUPP: start-on-event=EraseBlock, operation=PS_NVM_BLOCK_DLOG_SVK_SYS_SUPP.EraseBlock
        OpEventEraseBlock_EraseBlock_PS_NVM_BLOCK_DLOG_SVK_PLANT: start-on-event=EraseBlock, operation=PS_NVM_BLOCK_DLOG_SVK_PLANT.EraseBlock
        OpEventSetBlockProtection_SetBlockProtection_PAdmin_NVM_BLOCK_DLOG_SVK_SYS_SUPP: start-on-event=SetBlockProtection, operation=PAdmin_NVM_BLOCK_DLOG_SVK_SYS_SUPP.SetBlockProtection
        OpEventSetBlockProtection_SetBlockProtection_PAdmin_NVM_BLOCK_DLOG_SVK_PLANT: start-on-event=SetBlockProtection, operation=PAdmin_NVM_BLOCK_DLOG_SVK_PLANT.SetBlockProtection
        OpEventGetErrorStatus_GetErrorStatus_PS_Rte_NvmBlock_Darh_ErrorQueue: start-on-event=GetErrorStatus, operation=PS_Rte_NvmBlock_Darh_ErrorQueue.GetErrorStatus
        OpEventSetRamBlockStatus_SetRamBlockStatus_PS_Rte_NvmBlock_Darh_ErrorQueue: start-on-event=SetRamBlockStatus, operation=PS_Rte_NvmBlock_Darh_ErrorQueue.SetRamBlockStatus
        OpEventReadBlock_ReadBlock_PS_Rte_NvmBlock_Darh_ErrorQueue: start-on-event=ReadBlock, operation=PS_Rte_NvmBlock_Darh_ErrorQueue.ReadBlock
        OpEventWriteBlock_WriteBlock_PS_Rte_NvmBlock_Darh_ErrorQueue: start-on-event=WriteBlock, operation=PS_Rte_NvmBlock_Darh_ErrorQueue.WriteBlock
        OpEventInvalidateNvBlock_InvalidateNvBlock_PS_Rte_NvmBlock_Darh_ErrorQueue: start-on-event=InvalidateNvBlock, operation=PS_Rte_NvmBlock_Darh_ErrorQueue.InvalidateNvBlock
        OpEventEraseBlock_EraseBlock_PS_Rte_NvmBlock_Darh_ErrorQueue: start-on-event=EraseBlock, operation=PS_Rte_NvmBlock_Darh_ErrorQueue.EraseBlock
        OpEventSetBlockProtection_SetBlockProtection_PAdmin_Rte_NvmBlock_Darh_ErrorQueue: start-on-event=SetBlockProtection, operation=PAdmin_Rte_NvmBlock_Darh_ErrorQueue.SetBlockProtection
        OpEventGetErrorStatus_GetErrorStatus_PS_Rte_NvmBlock_CDD_VrfyCritReg_MCalReadVrfyCritRegFltInfo: start-on-event=GetErrorStatus, operation=PS_Rte_NvmBlock_CDD_VrfyCritReg_MCalReadVrfyCritRegFltInfo.GetErrorStatus
        OpEventSetRamBlockStatus_SetRamBlockStatus_PS_Rte_NvmBlock_CDD_VrfyCritReg_MCalReadVrfyCritRegFltInfo: start-on-event=SetRamBlockStatus, operation=PS_Rte_NvmBlock_CDD_VrfyCritReg_MCalReadVrfyCritRegFltInfo.SetRamBlockStatus
        OpEventReadBlock_ReadBlock_PS_Rte_NvmBlock_CDD_VrfyCritReg_MCalReadVrfyCritRegFltInfo: start-on-event=ReadBlock, operation=PS_Rte_NvmBlock_CDD_VrfyCritReg_MCalReadVrfyCritRegFltInfo.ReadBlock
        OpEventWriteBlock_WriteBlock_PS_Rte_NvmBlock_CDD_VrfyCritReg_MCalReadVrfyCritRegFltInfo: start-on-event=WriteBlock, operation=PS_Rte_NvmBlock_CDD_VrfyCritReg_MCalReadVrfyCritRegFltInfo.WriteBlock
        OpEventInvalidateNvBlock_InvalidateNvBlock_PS_Rte_NvmBlock_CDD_VrfyCritReg_MCalReadVrfyCritRegFltInfo: start-on-event=InvalidateNvBlock, operation=PS_Rte_NvmBlock_CDD_VrfyCritReg_MCalReadVrfyCritRegFltInfo.InvalidateNvBlock
        OpEventEraseBlock_EraseBlock_PS_Rte_NvmBlock_CDD_VrfyCritReg_MCalReadVrfyCritRegFltInfo: start-on-event=EraseBlock, operation=PS_Rte_NvmBlock_CDD_VrfyCritReg_MCalReadVrfyCritRegFltInfo.EraseBlock
        OpEventSetBlockProtection_SetBlockProtection_PAdmin_Rte_NvmBlock_CDD_VrfyCritReg_MCalReadVrfyCritRegFltInfo: start-on-event=SetBlockProtection, operation=PAdmin_Rte_NvmBlock_CDD_VrfyCritReg_MCalReadVrfyCritRegFltInfo.SetBlockProtection
        OpEventGetErrorStatus_GetErrorStatus_PS_Rte_NvmBlock_BmwHwAgArbnAndEotPosn_BmwVehCentrOffs: start-on-event=GetErrorStatus, operation=PS_Rte_NvmBlock_BmwHwAgArbnAndEotPosn_BmwVehCentrOffs.GetErrorStatus
        OpEventSetRamBlockStatus_SetRamBlockStatus_PS_Rte_NvmBlock_BmwHwAgArbnAndEotPosn_BmwVehCentrOffs: start-on-event=SetRamBlockStatus, operation=PS_Rte_NvmBlock_BmwHwAgArbnAndEotPosn_BmwVehCentrOffs.SetRamBlockStatus
        OpEventReadBlock_ReadBlock_PS_Rte_NvmBlock_BmwHwAgArbnAndEotPosn_BmwVehCentrOffs: start-on-event=ReadBlock, operation=PS_Rte_NvmBlock_BmwHwAgArbnAndEotPosn_BmwVehCentrOffs.ReadBlock
        OpEventWriteBlock_WriteBlock_PS_Rte_NvmBlock_BmwHwAgArbnAndEotPosn_BmwVehCentrOffs: start-on-event=WriteBlock, operation=PS_Rte_NvmBlock_BmwHwAgArbnAndEotPosn_BmwVehCentrOffs.WriteBlock
        OpEventInvalidateNvBlock_InvalidateNvBlock_PS_Rte_NvmBlock_BmwHwAgArbnAndEotPosn_BmwVehCentrOffs: start-on-event=InvalidateNvBlock, operation=PS_Rte_NvmBlock_BmwHwAgArbnAndEotPosn_BmwVehCentrOffs.InvalidateNvBlock
        OpEventEraseBlock_EraseBlock_PS_Rte_NvmBlock_BmwHwAgArbnAndEotPosn_BmwVehCentrOffs: start-on-event=EraseBlock, operation=PS_Rte_NvmBlock_BmwHwAgArbnAndEotPosn_BmwVehCentrOffs.EraseBlock
        OpEventSetBlockProtection_SetBlockProtection_PAdmin_Rte_NvmBlock_BmwHwAgArbnAndEotPosn_BmwVehCentrOffs: start-on-event=SetBlockProtection, operation=PAdmin_Rte_NvmBlock_BmwHwAgArbnAndEotPosn_BmwVehCentrOffs.SetBlockProtection
        OpEventGetErrorStatus_GetErrorStatus_PS_Rte_NvmBlock_LrndRackCentr_LrndRackCentr: start-on-event=GetErrorStatus, operation=PS_Rte_NvmBlock_LrndRackCentr_LrndRackCentr.GetErrorStatus
        OpEventSetRamBlockStatus_SetRamBlockStatus_PS_Rte_NvmBlock_LrndRackCentr_LrndRackCentr: start-on-event=SetRamBlockStatus, operation=PS_Rte_NvmBlock_LrndRackCentr_LrndRackCentr.SetRamBlockStatus
        OpEventReadBlock_ReadBlock_PS_Rte_NvmBlock_LrndRackCentr_LrndRackCentr: start-on-event=ReadBlock, operation=PS_Rte_NvmBlock_LrndRackCentr_LrndRackCentr.ReadBlock
        OpEventWriteBlock_WriteBlock_PS_Rte_NvmBlock_LrndRackCentr_LrndRackCentr: start-on-event=WriteBlock, operation=PS_Rte_NvmBlock_LrndRackCentr_LrndRackCentr.WriteBlock
        OpEventInvalidateNvBlock_InvalidateNvBlock_PS_Rte_NvmBlock_LrndRackCentr_LrndRackCentr: start-on-event=InvalidateNvBlock, operation=PS_Rte_NvmBlock_LrndRackCentr_LrndRackCentr.InvalidateNvBlock
        OpEventEraseBlock_EraseBlock_PS_Rte_NvmBlock_LrndRackCentr_LrndRackCentr: start-on-event=EraseBlock, operation=PS_Rte_NvmBlock_LrndRackCentr_LrndRackCentr.EraseBlock
        OpEventSetBlockProtection_SetBlockProtection_PAdmin_Rte_NvmBlock_LrndRackCentr_LrndRackCentr: start-on-event=SetBlockProtection, operation=PAdmin_Rte_NvmBlock_LrndRackCentr_LrndRackCentr.SetBlockProtection
        OpEventGetErrorStatus_GetErrorStatus_PS_Rte_NvmBlock_ExcpnHndlg_McuDiagcData: start-on-event=GetErrorStatus, operation=PS_Rte_NvmBlock_ExcpnHndlg_McuDiagcData.GetErrorStatus
        OpEventSetRamBlockStatus_SetRamBlockStatus_PS_Rte_NvmBlock_ExcpnHndlg_McuDiagcData: start-on-event=SetRamBlockStatus, operation=PS_Rte_NvmBlock_ExcpnHndlg_McuDiagcData.SetRamBlockStatus
        OpEventReadBlock_ReadBlock_PS_Rte_NvmBlock_ExcpnHndlg_McuDiagcData: start-on-event=ReadBlock, operation=PS_Rte_NvmBlock_ExcpnHndlg_McuDiagcData.ReadBlock
        OpEventWriteBlock_WriteBlock_PS_Rte_NvmBlock_ExcpnHndlg_McuDiagcData: start-on-event=WriteBlock, operation=PS_Rte_NvmBlock_ExcpnHndlg_McuDiagcData.WriteBlock
        OpEventInvalidateNvBlock_InvalidateNvBlock_PS_Rte_NvmBlock_ExcpnHndlg_McuDiagcData: start-on-event=InvalidateNvBlock, operation=PS_Rte_NvmBlock_ExcpnHndlg_McuDiagcData.InvalidateNvBlock
        OpEventEraseBlock_EraseBlock_PS_Rte_NvmBlock_ExcpnHndlg_McuDiagcData: start-on-event=EraseBlock, operation=PS_Rte_NvmBlock_ExcpnHndlg_McuDiagcData.EraseBlock
        OpEventSetBlockProtection_SetBlockProtection_PAdmin_Rte_NvmBlock_ExcpnHndlg_McuDiagcData: start-on-event=SetBlockProtection, operation=PAdmin_Rte_NvmBlock_ExcpnHndlg_McuDiagcData.SetBlockProtection
        OpEventRestoreBlockDefaults_RestoreBlockDefaults_PS_Rte_NvmBlock_ExcpnHndlg_McuDiagcData: start-on-event=RestoreBlockDefaults, operation=PS_Rte_NvmBlock_ExcpnHndlg_McuDiagcData.RestoreBlockDefaults
        OpEventGetErrorStatus_GetErrorStatus_PS_Rte_NvmBlock_TEstimn_TFilStVal: start-on-event=GetErrorStatus, operation=PS_Rte_NvmBlock_TEstimn_TFilStVal.GetErrorStatus
        OpEventSetRamBlockStatus_SetRamBlockStatus_PS_Rte_NvmBlock_TEstimn_TFilStVal: start-on-event=SetRamBlockStatus, operation=PS_Rte_NvmBlock_TEstimn_TFilStVal.SetRamBlockStatus
        OpEventReadBlock_ReadBlock_PS_Rte_NvmBlock_TEstimn_TFilStVal: start-on-event=ReadBlock, operation=PS_Rte_NvmBlock_TEstimn_TFilStVal.ReadBlock
        OpEventWriteBlock_WriteBlock_PS_Rte_NvmBlock_TEstimn_TFilStVal: start-on-event=WriteBlock, operation=PS_Rte_NvmBlock_TEstimn_TFilStVal.WriteBlock
        OpEventInvalidateNvBlock_InvalidateNvBlock_PS_Rte_NvmBlock_TEstimn_TFilStVal: start-on-event=InvalidateNvBlock, operation=PS_Rte_NvmBlock_TEstimn_TFilStVal.InvalidateNvBlock
        OpEventEraseBlock_EraseBlock_PS_Rte_NvmBlock_TEstimn_TFilStVal: start-on-event=EraseBlock, operation=PS_Rte_NvmBlock_TEstimn_TFilStVal.EraseBlock
        OpEventSetBlockProtection_SetBlockProtection_PAdmin_Rte_NvmBlock_TEstimn_TFilStVal: start-on-event=SetBlockProtection, operation=PAdmin_Rte_NvmBlock_TEstimn_TFilStVal.SetBlockProtection
        OpEventGetErrorStatus_GetErrorStatus_PS_NVM_BLOCK_DLOG_SVK_ENTRY: start-on-event=GetErrorStatus, operation=PS_NVM_BLOCK_DLOG_SVK_ENTRY.GetErrorStatus
        OpEventSetRamBlockStatus_SetRamBlockStatus_PS_NVM_BLOCK_DLOG_SVK_ENTRY: start-on-event=SetRamBlockStatus, operation=PS_NVM_BLOCK_DLOG_SVK_ENTRY.SetRamBlockStatus
        OpEventReadBlock_ReadBlock_PS_NVM_BLOCK_DLOG_SVK_ENTRY: start-on-event=ReadBlock, operation=PS_NVM_BLOCK_DLOG_SVK_ENTRY.ReadBlock
        OpEventWriteBlock_WriteBlock_PS_NVM_BLOCK_DLOG_SVK_ENTRY: start-on-event=WriteBlock, operation=PS_NVM_BLOCK_DLOG_SVK_ENTRY.WriteBlock
        OpEventInvalidateNvBlock_InvalidateNvBlock_PS_NVM_BLOCK_DLOG_SVK_ENTRY: start-on-event=InvalidateNvBlock, operation=PS_NVM_BLOCK_DLOG_SVK_ENTRY.InvalidateNvBlock
        OpEventEraseBlock_EraseBlock_PS_NVM_BLOCK_DLOG_SVK_ENTRY: start-on-event=EraseBlock, operation=PS_NVM_BLOCK_DLOG_SVK_ENTRY.EraseBlock
        OpEventSetBlockProtection_SetBlockProtection_PAdmin_NVM_BLOCK_DLOG_SVK_ENTRY: start-on-event=SetBlockProtection, operation=PAdmin_NVM_BLOCK_DLOG_SVK_ENTRY.SetBlockProtection
        OpEventSetDataIndex_SetDataIndex_PS_NVM_BLOCK_DLOG_SVK_ENTRY: start-on-event=SetDataIndex, operation=PS_NVM_BLOCK_DLOG_SVK_ENTRY.SetDataIndex
        OpEventGetDataIndex_GetDataIndex_PS_NVM_BLOCK_DLOG_SVK_ENTRY: start-on-event=GetDataIndex, operation=PS_NVM_BLOCK_DLOG_SVK_ENTRY.GetDataIndex
        OpEventRestoreBlockDefaults_RestoreBlockDefaults_PS_NVM_BLOCK_BOOT_SVK_HISTORY: start-on-event=RestoreBlockDefaults, operation=PS_NVM_BLOCK_BOOT_SVK_HISTORY.RestoreBlockDefaults
        OpEventRestoreBlockDefaults_RestoreBlockDefaults_PS_NVM_BLOCK_BOOT_PROG_DATA: start-on-event=RestoreBlockDefaults, operation=PS_NVM_BLOCK_BOOT_PROG_DATA.RestoreBlockDefaults
        OpEventGetErrorStatus_GetErrorStatus_PS_Rte_NvmBlock_Darh_DiagnoseMasterEnable: start-on-event=GetErrorStatus, operation=PS_Rte_NvmBlock_Darh_DiagnoseMasterEnable.GetErrorStatus
        OpEventSetRamBlockStatus_SetRamBlockStatus_PS_Rte_NvmBlock_Darh_DiagnoseMasterEnable: start-on-event=SetRamBlockStatus, operation=PS_Rte_NvmBlock_Darh_DiagnoseMasterEnable.SetRamBlockStatus
        OpEventReadBlock_ReadBlock_PS_Rte_NvmBlock_Darh_DiagnoseMasterEnable: start-on-event=ReadBlock, operation=PS_Rte_NvmBlock_Darh_DiagnoseMasterEnable.ReadBlock
        OpEventWriteBlock_WriteBlock_PS_Rte_NvmBlock_Darh_DiagnoseMasterEnable: start-on-event=WriteBlock, operation=PS_Rte_NvmBlock_Darh_DiagnoseMasterEnable.WriteBlock
        OpEventInvalidateNvBlock_InvalidateNvBlock_PS_Rte_NvmBlock_Darh_DiagnoseMasterEnable: start-on-event=InvalidateNvBlock, operation=PS_Rte_NvmBlock_Darh_DiagnoseMasterEnable.InvalidateNvBlock
        OpEventEraseBlock_EraseBlock_PS_Rte_NvmBlock_Darh_DiagnoseMasterEnable: start-on-event=EraseBlock, operation=PS_Rte_NvmBlock_Darh_DiagnoseMasterEnable.EraseBlock
        OpEventSetBlockProtection_SetBlockProtection_PAdmin_Rte_NvmBlock_Darh_DiagnoseMasterEnable: start-on-event=SetBlockProtection, operation=PAdmin_Rte_NvmBlock_Darh_DiagnoseMasterEnable.SetBlockProtection
        OpEventGetErrorStatus_GetErrorStatus_PS_Rte_NvmBlock_BmwTunSetHndlr_BmwDesIninIdx: start-on-event=GetErrorStatus, operation=PS_Rte_NvmBlock_BmwTunSetHndlr_BmwDesIninIdx.GetErrorStatus
        OpEventSetRamBlockStatus_SetRamBlockStatus_PS_Rte_NvmBlock_BmwTunSetHndlr_BmwDesIninIdx: start-on-event=SetRamBlockStatus, operation=PS_Rte_NvmBlock_BmwTunSetHndlr_BmwDesIninIdx.SetRamBlockStatus
        OpEventReadBlock_ReadBlock_PS_Rte_NvmBlock_BmwTunSetHndlr_BmwDesIninIdx: start-on-event=ReadBlock, operation=PS_Rte_NvmBlock_BmwTunSetHndlr_BmwDesIninIdx.ReadBlock
        OpEventWriteBlock_WriteBlock_PS_Rte_NvmBlock_BmwTunSetHndlr_BmwDesIninIdx: start-on-event=WriteBlock, operation=PS_Rte_NvmBlock_BmwTunSetHndlr_BmwDesIninIdx.WriteBlock
        OpEventInvalidateNvBlock_InvalidateNvBlock_PS_Rte_NvmBlock_BmwTunSetHndlr_BmwDesIninIdx: start-on-event=InvalidateNvBlock, operation=PS_Rte_NvmBlock_BmwTunSetHndlr_BmwDesIninIdx.InvalidateNvBlock
        OpEventEraseBlock_EraseBlock_PS_Rte_NvmBlock_BmwTunSetHndlr_BmwDesIninIdx: start-on-event=EraseBlock, operation=PS_Rte_NvmBlock_BmwTunSetHndlr_BmwDesIninIdx.EraseBlock
        OpEventSetBlockProtection_SetBlockProtection_PAdmin_Rte_NvmBlock_BmwTunSetHndlr_BmwDesIninIdx: start-on-event=SetBlockProtection, operation=PAdmin_Rte_NvmBlock_BmwTunSetHndlr_BmwDesIninIdx.SetBlockProtection
        OpEventRestoreBlockDefaults_RestoreBlockDefaults_PS_Rte_NvmBlock_BmwTunSetHndlr_BmwDesIninIdx: start-on-event=RestoreBlockDefaults, operation=PS_Rte_NvmBlock_BmwTunSetHndlr_BmwDesIninIdx.RestoreBlockDefaults
        OpEventGetErrorStatus_GetErrorStatus_PS_Rte_NvmBlock_Coding_CodingData: start-on-event=GetErrorStatus, operation=PS_Rte_NvmBlock_Coding_CodingData.GetErrorStatus
        OpEventSetRamBlockStatus_SetRamBlockStatus_PS_Rte_NvmBlock_Coding_CodingData: start-on-event=SetRamBlockStatus, operation=PS_Rte_NvmBlock_Coding_CodingData.SetRamBlockStatus
        OpEventReadBlock_ReadBlock_PS_Rte_NvmBlock_Coding_CodingData: start-on-event=ReadBlock, operation=PS_Rte_NvmBlock_Coding_CodingData.ReadBlock
        OpEventWriteBlock_WriteBlock_PS_Rte_NvmBlock_Coding_CodingData: start-on-event=WriteBlock, operation=PS_Rte_NvmBlock_Coding_CodingData.WriteBlock
        OpEventInvalidateNvBlock_InvalidateNvBlock_PS_Rte_NvmBlock_Coding_CodingData: start-on-event=InvalidateNvBlock, operation=PS_Rte_NvmBlock_Coding_CodingData.InvalidateNvBlock
        OpEventEraseBlock_EraseBlock_PS_Rte_NvmBlock_Coding_CodingData: start-on-event=EraseBlock, operation=PS_Rte_NvmBlock_Coding_CodingData.EraseBlock
        OpEventSetBlockProtection_SetBlockProtection_PAdmin_Rte_NvmBlock_Coding_CodingData: start-on-event=SetBlockProtection, operation=PAdmin_Rte_NvmBlock_Coding_CodingData.SetBlockProtection
        OpEventRestoreBlockDefaults_RestoreBlockDefaults_PS_Rte_NvmBlock_Coding_CodingData: start-on-event=RestoreBlockDefaults, operation=PS_Rte_NvmBlock_Coding_CodingData.RestoreBlockDefaults
        OpEventGetErrorStatus_GetErrorStatus_PS_Rte_NvmBlock_BmwTunSetHndlr_NvmBmwDesIninOptSetAIdx: start-on-event=GetErrorStatus, operation=PS_Rte_NvmBlock_BmwTunSetHndlr_NvmBmwDesIninOptSetAIdx.GetErrorStatus
        OpEventSetRamBlockStatus_SetRamBlockStatus_PS_Rte_NvmBlock_BmwTunSetHndlr_NvmBmwDesIninOptSetAIdx: start-on-event=SetRamBlockStatus, operation=PS_Rte_NvmBlock_BmwTunSetHndlr_NvmBmwDesIninOptSetAIdx.SetRamBlockStatus
        OpEventReadBlock_ReadBlock_PS_Rte_NvmBlock_BmwTunSetHndlr_NvmBmwDesIninOptSetAIdx: start-on-event=ReadBlock, operation=PS_Rte_NvmBlock_BmwTunSetHndlr_NvmBmwDesIninOptSetAIdx.ReadBlock
        OpEventWriteBlock_WriteBlock_PS_Rte_NvmBlock_BmwTunSetHndlr_NvmBmwDesIninOptSetAIdx: start-on-event=WriteBlock, operation=PS_Rte_NvmBlock_BmwTunSetHndlr_NvmBmwDesIninOptSetAIdx.WriteBlock
        OpEventInvalidateNvBlock_InvalidateNvBlock_PS_Rte_NvmBlock_BmwTunSetHndlr_NvmBmwDesIninOptSetAIdx: start-on-event=InvalidateNvBlock, operation=PS_Rte_NvmBlock_BmwTunSetHndlr_NvmBmwDesIninOptSetAIdx.InvalidateNvBlock
        OpEventEraseBlock_EraseBlock_PS_Rte_NvmBlock_BmwTunSetHndlr_NvmBmwDesIninOptSetAIdx: start-on-event=EraseBlock, operation=PS_Rte_NvmBlock_BmwTunSetHndlr_NvmBmwDesIninOptSetAIdx.EraseBlock
        OpEventSetBlockProtection_SetBlockProtection_PAdmin_Rte_NvmBlock_BmwTunSetHndlr_NvmBmwDesIninOptSetAIdx: start-on-event=SetBlockProtection, operation=PAdmin_Rte_NvmBlock_BmwTunSetHndlr_NvmBmwDesIninOptSetAIdx.SetBlockProtection
        OpEventRestoreBlockDefaults_RestoreBlockDefaults_PS_Rte_NvmBlock_BmwTunSetHndlr_NvmBmwDesIninOptSetAIdx: start-on-event=RestoreBlockDefaults, operation=PS_Rte_NvmBlock_BmwTunSetHndlr_NvmBmwDesIninOptSetAIdx.RestoreBlockDefaults
        OpEventGetErrorStatus_GetErrorStatus_PS_Rte_NvmBlock_BmwDiagcSrvHndlg_MilesKmEeprom: start-on-event=GetErrorStatus, operation=PS_Rte_NvmBlock_BmwDiagcSrvHndlg_MilesKmEeprom.GetErrorStatus
        OpEventSetRamBlockStatus_SetRamBlockStatus_PS_Rte_NvmBlock_BmwDiagcSrvHndlg_MilesKmEeprom: start-on-event=SetRamBlockStatus, operation=PS_Rte_NvmBlock_BmwDiagcSrvHndlg_MilesKmEeprom.SetRamBlockStatus
        OpEventReadBlock_ReadBlock_PS_Rte_NvmBlock_BmwDiagcSrvHndlg_MilesKmEeprom: start-on-event=ReadBlock, operation=PS_Rte_NvmBlock_BmwDiagcSrvHndlg_MilesKmEeprom.ReadBlock
        OpEventWriteBlock_WriteBlock_PS_Rte_NvmBlock_BmwDiagcSrvHndlg_MilesKmEeprom: start-on-event=WriteBlock, operation=PS_Rte_NvmBlock_BmwDiagcSrvHndlg_MilesKmEeprom.WriteBlock
        OpEventInvalidateNvBlock_InvalidateNvBlock_PS_Rte_NvmBlock_BmwDiagcSrvHndlg_MilesKmEeprom: start-on-event=InvalidateNvBlock, operation=PS_Rte_NvmBlock_BmwDiagcSrvHndlg_MilesKmEeprom.InvalidateNvBlock
        OpEventEraseBlock_EraseBlock_PS_Rte_NvmBlock_BmwDiagcSrvHndlg_MilesKmEeprom: start-on-event=EraseBlock, operation=PS_Rte_NvmBlock_BmwDiagcSrvHndlg_MilesKmEeprom.EraseBlock
        OpEventSetBlockProtection_SetBlockProtection_PAdmin_Rte_NvmBlock_BmwDiagcSrvHndlg_MilesKmEeprom: start-on-event=SetBlockProtection, operation=PAdmin_Rte_NvmBlock_BmwDiagcSrvHndlg_MilesKmEeprom.SetBlockProtection
        OpEventGetErrorStatus_GetErrorStatus_PS_Rte_NvmBlock_BmwDiagcSrvHndlg_ProgCntr: start-on-event=GetErrorStatus, operation=PS_Rte_NvmBlock_BmwDiagcSrvHndlg_ProgCntr.GetErrorStatus
        OpEventSetRamBlockStatus_SetRamBlockStatus_PS_Rte_NvmBlock_BmwDiagcSrvHndlg_ProgCntr: start-on-event=SetRamBlockStatus, operation=PS_Rte_NvmBlock_BmwDiagcSrvHndlg_ProgCntr.SetRamBlockStatus
        OpEventReadBlock_ReadBlock_PS_Rte_NvmBlock_BmwDiagcSrvHndlg_ProgCntr: start-on-event=ReadBlock, operation=PS_Rte_NvmBlock_BmwDiagcSrvHndlg_ProgCntr.ReadBlock
        OpEventWriteBlock_WriteBlock_PS_Rte_NvmBlock_BmwDiagcSrvHndlg_ProgCntr: start-on-event=WriteBlock, operation=PS_Rte_NvmBlock_BmwDiagcSrvHndlg_ProgCntr.WriteBlock
        OpEventInvalidateNvBlock_InvalidateNvBlock_PS_Rte_NvmBlock_BmwDiagcSrvHndlg_ProgCntr: start-on-event=InvalidateNvBlock, operation=PS_Rte_NvmBlock_BmwDiagcSrvHndlg_ProgCntr.InvalidateNvBlock
        OpEventEraseBlock_EraseBlock_PS_Rte_NvmBlock_BmwDiagcSrvHndlg_ProgCntr: start-on-event=EraseBlock, operation=PS_Rte_NvmBlock_BmwDiagcSrvHndlg_ProgCntr.EraseBlock
        OpEventSetBlockProtection_SetBlockProtection_PAdmin_Rte_NvmBlock_BmwDiagcSrvHndlg_ProgCntr: start-on-event=SetBlockProtection, operation=PAdmin_Rte_NvmBlock_BmwDiagcSrvHndlg_ProgCntr.SetBlockProtection
        OpEventGetErrorStatus_GetErrorStatus_PS_Rte_NvmBlock_BmwDiagcSrvHndlg_ProgCntrMaxVal: start-on-event=GetErrorStatus, operation=PS_Rte_NvmBlock_BmwDiagcSrvHndlg_ProgCntrMaxVal.GetErrorStatus
        OpEventSetRamBlockStatus_SetRamBlockStatus_PS_Rte_NvmBlock_BmwDiagcSrvHndlg_ProgCntrMaxVal: start-on-event=SetRamBlockStatus, operation=PS_Rte_NvmBlock_BmwDiagcSrvHndlg_ProgCntrMaxVal.SetRamBlockStatus
        OpEventReadBlock_ReadBlock_PS_Rte_NvmBlock_BmwDiagcSrvHndlg_ProgCntrMaxVal: start-on-event=ReadBlock, operation=PS_Rte_NvmBlock_BmwDiagcSrvHndlg_ProgCntrMaxVal.ReadBlock
        OpEventWriteBlock_WriteBlock_PS_Rte_NvmBlock_BmwDiagcSrvHndlg_ProgCntrMaxVal: start-on-event=WriteBlock, operation=PS_Rte_NvmBlock_BmwDiagcSrvHndlg_ProgCntrMaxVal.WriteBlock
        OpEventInvalidateNvBlock_InvalidateNvBlock_PS_Rte_NvmBlock_BmwDiagcSrvHndlg_ProgCntrMaxVal: start-on-event=InvalidateNvBlock, operation=PS_Rte_NvmBlock_BmwDiagcSrvHndlg_ProgCntrMaxVal.InvalidateNvBlock
        OpEventEraseBlock_EraseBlock_PS_Rte_NvmBlock_BmwDiagcSrvHndlg_ProgCntrMaxVal: start-on-event=EraseBlock, operation=PS_Rte_NvmBlock_BmwDiagcSrvHndlg_ProgCntrMaxVal.EraseBlock
        OpEventSetBlockProtection_SetBlockProtection_PAdmin_Rte_NvmBlock_BmwDiagcSrvHndlg_ProgCntrMaxVal: start-on-event=SetBlockProtection, operation=PAdmin_Rte_NvmBlock_BmwDiagcSrvHndlg_ProgCntrMaxVal.SetBlockProtection
        OpEventRestoreBlockDefaults_RestoreBlockDefaults_PS_Rte_NvmBlock_BmwDiagcSrvHndlg_ProgCntrMaxVal: start-on-event=RestoreBlockDefaults, operation=PS_Rte_NvmBlock_BmwDiagcSrvHndlg_ProgCntrMaxVal.RestoreBlockDefaults
        OpEventGetErrorStatus_GetErrorStatus_PS_Rte_NvmBlock_BmwDiagcSrvHndlg_TestStamp: start-on-event=GetErrorStatus, operation=PS_Rte_NvmBlock_BmwDiagcSrvHndlg_TestStamp.GetErrorStatus
        OpEventSetRamBlockStatus_SetRamBlockStatus_PS_Rte_NvmBlock_BmwDiagcSrvHndlg_TestStamp: start-on-event=SetRamBlockStatus, operation=PS_Rte_NvmBlock_BmwDiagcSrvHndlg_TestStamp.SetRamBlockStatus
        OpEventReadBlock_ReadBlock_PS_Rte_NvmBlock_BmwDiagcSrvHndlg_TestStamp: start-on-event=ReadBlock, operation=PS_Rte_NvmBlock_BmwDiagcSrvHndlg_TestStamp.ReadBlock
        OpEventWriteBlock_WriteBlock_PS_Rte_NvmBlock_BmwDiagcSrvHndlg_TestStamp: start-on-event=WriteBlock, operation=PS_Rte_NvmBlock_BmwDiagcSrvHndlg_TestStamp.WriteBlock
        OpEventInvalidateNvBlock_InvalidateNvBlock_PS_Rte_NvmBlock_BmwDiagcSrvHndlg_TestStamp: start-on-event=InvalidateNvBlock, operation=PS_Rte_NvmBlock_BmwDiagcSrvHndlg_TestStamp.InvalidateNvBlock
        OpEventEraseBlock_EraseBlock_PS_Rte_NvmBlock_BmwDiagcSrvHndlg_TestStamp: start-on-event=EraseBlock, operation=PS_Rte_NvmBlock_BmwDiagcSrvHndlg_TestStamp.EraseBlock
        OpEventSetBlockProtection_SetBlockProtection_PAdmin_Rte_NvmBlock_BmwDiagcSrvHndlg_TestStamp: start-on-event=SetBlockProtection, operation=PAdmin_Rte_NvmBlock_BmwDiagcSrvHndlg_TestStamp.SetBlockProtection
        OpEventGetErrorStatus_GetErrorStatus_PS_Rte_NvmBlock_PullCmpActv_PullCmpLongTerm: start-on-event=GetErrorStatus, operation=PS_Rte_NvmBlock_PullCmpActv_PullCmpLongTerm.GetErrorStatus
        OpEventSetRamBlockStatus_SetRamBlockStatus_PS_Rte_NvmBlock_PullCmpActv_PullCmpLongTerm: start-on-event=SetRamBlockStatus, operation=PS_Rte_NvmBlock_PullCmpActv_PullCmpLongTerm.SetRamBlockStatus
        OpEventReadBlock_ReadBlock_PS_Rte_NvmBlock_PullCmpActv_PullCmpLongTerm: start-on-event=ReadBlock, operation=PS_Rte_NvmBlock_PullCmpActv_PullCmpLongTerm.ReadBlock
        OpEventWriteBlock_WriteBlock_PS_Rte_NvmBlock_PullCmpActv_PullCmpLongTerm: start-on-event=WriteBlock, operation=PS_Rte_NvmBlock_PullCmpActv_PullCmpLongTerm.WriteBlock
        OpEventInvalidateNvBlock_InvalidateNvBlock_PS_Rte_NvmBlock_PullCmpActv_PullCmpLongTerm: start-on-event=InvalidateNvBlock, operation=PS_Rte_NvmBlock_PullCmpActv_PullCmpLongTerm.InvalidateNvBlock
        OpEventEraseBlock_EraseBlock_PS_Rte_NvmBlock_PullCmpActv_PullCmpLongTerm: start-on-event=EraseBlock, operation=PS_Rte_NvmBlock_PullCmpActv_PullCmpLongTerm.EraseBlock
        OpEventSetBlockProtection_SetBlockProtection_PAdmin_Rte_NvmBlock_PullCmpActv_PullCmpLongTerm: start-on-event=SetBlockProtection, operation=PAdmin_Rte_NvmBlock_PullCmpActv_PullCmpLongTerm.SetBlockProtection
        OpEventRestoreBlockDefaults_RestoreBlockDefaults_PS_Rte_NvmBlock_PullCmpActv_PullCmpLongTerm: start-on-event=RestoreBlockDefaults, operation=PS_Rte_NvmBlock_PullCmpActv_PullCmpLongTerm.RestoreBlockDefaults
      port-api-options:
        enable-take-address=true, indirect-api=false, port=NvM_RpNotifyJobEnd_Rte_NvmBlock_Vin
        enable-take-address=true, indirect-api=false, port=NvM_RpNotifyInit_NVM_BLOCK_BOOT_PROG_COUNTER
        enable-take-address=true, indirect-api=false, port=NvM_RpNotifyJobEnd_NVM_BLOCK_BOOT_PROG_COUNTER
        enable-take-address=true, indirect-api=false, port=NvM_RpNotifyJobEnd_NVM_BLOCK_BOOT_SVK_HISTORY
        enable-take-address=true, indirect-api=false, port=NvM_RpNotifyInit_NVM_BLOCK_BOOT_SVK_HISTORY
        enable-take-address=true, indirect-api=false, port=NvM_RpNotifyInit_NVM_BLOCK_BOOT_PROG_DATA
        enable-take-address=true, indirect-api=false, port=NvM_RpNotifyJobEnd_NVM_BLOCK_BOOT_PROG_DATA
        enable-take-address=true, indirect-api=false, port=NvM_RpNotifyJobEnd_Rte_NvmBlock_Omc
        enable-take-address=true, indirect-api=false, port=NvM_RpNotifyJobEnd_NVM_BLOCK_DLOG_SVK_ENTRY
        enable-take-address=true, indirect-api=false, port=NvM_RpNotifyJobEnd_Rte_NvmBlock_Darh_DiagnoseMasterEnable
        enable-take-address=true, indirect-api=false, port=NvM_RpNotifyJobEnd_Rte_NvmBlock_Coding_CodingData
        {enable-take-address=true, indirect-api=false, port-defined-argument-value{value=58, value-type=NvM_BlockIdType}, port=PS_Rte_NvmBlock_CDD_NvMProxy_ShtdwnClsChk}
        {enable-take-address=true, indirect-api=false, port-defined-argument-value{value=58, value-type=NvM_BlockIdType}, port=PAdmin_Rte_NvmBlock_CDD_NvMProxy_ShtdwnClsChk}
        {enable-take-address=true, indirect-api=false, port-defined-argument-value{value=55, value-type=NvM_BlockIdType}, port=PS_Rte_NvmBlock_DiagcMgr_DiagcMgrApplCrc}
        {enable-take-address=true, indirect-api=false, port-defined-argument-value{value=55, value-type=NvM_BlockIdType}, port=PAdmin_Rte_NvmBlock_DiagcMgr_DiagcMgrApplCrc}
        {enable-take-address=true, indirect-api=false, port-defined-argument-value{value=56, value-type=NvM_BlockIdType}, port=PS_Rte_NvmBlock_DiagcMgr_DiagcMgrNtcFltAry}
        {enable-take-address=true, indirect-api=false, port-defined-argument-value{value=56, value-type=NvM_BlockIdType}, port=PAdmin_Rte_NvmBlock_DiagcMgr_DiagcMgrNtcFltAry}
        {enable-take-address=true, indirect-api=false, port-defined-argument-value{value=57, value-type=NvM_BlockIdType}, port=PS_Rte_NvmBlock_DiagcMgr_DiagcMgrLtchCntrAry}
        {enable-take-address=true, indirect-api=false, port-defined-argument-value{value=57, value-type=NvM_BlockIdType}, port=PAdmin_Rte_NvmBlock_DiagcMgr_DiagcMgrLtchCntrAry}
        {enable-take-address=true, indirect-api=false, port-defined-argument-value{value=54, value-type=NvM_BlockIdType}, port=PS_Rte_NvmBlock_CDD_MotAg0Meas_MotAg0CoeffTbl}
        {enable-take-address=true, indirect-api=false, port-defined-argument-value{value=54, value-type=NvM_BlockIdType}, port=PAdmin_Rte_NvmBlock_CDD_MotAg0Meas_MotAg0CoeffTbl}
        {enable-take-address=true, indirect-api=false, port-defined-argument-value{value=53, value-type=NvM_BlockIdType}, port=PS_Rte_NvmBlock_CDD_MotAg1Meas_MotAg1CoeffTbl}
        {enable-take-address=true, indirect-api=false, port-defined-argument-value{value=53, value-type=NvM_BlockIdType}, port=PAdmin_Rte_NvmBlock_CDD_MotAg1Meas_MotAg1CoeffTbl}
        {enable-take-address=true, indirect-api=false, port-defined-argument-value{value=52, value-type=NvM_BlockIdType}, port=PS_Rte_NvmBlock_CDD_CurrMeas_CurrMeasEolGainCalSetABC}
        {enable-take-address=true, indirect-api=false, port-defined-argument-value{value=52, value-type=NvM_BlockIdType}, port=PAdmin_Rte_NvmBlock_CDD_CurrMeas_CurrMeasEolGainCalSetABC}
        {enable-take-address=true, indirect-api=false, port-defined-argument-value{value=51, value-type=NvM_BlockIdType}, port=PS_Rte_NvmBlock_CDD_CurrMeas_CurrMeasEolOffsCalSetABC}
        {enable-take-address=true, indirect-api=false, port-defined-argument-value{value=51, value-type=NvM_BlockIdType}, port=PAdmin_Rte_NvmBlock_CDD_CurrMeas_CurrMeasEolOffsCalSetABC}
        {enable-take-address=true, indirect-api=false, port-defined-argument-value{value=49, value-type=NvM_BlockIdType}, port=PS_Rte_NvmBlock_CmnMfgSrv_CcaHwPartNr}
        {enable-take-address=true, indirect-api=false, port-defined-argument-value{value=49, value-type=NvM_BlockIdType}, port=PAdmin_Rte_NvmBlock_CmnMfgSrv_CcaHwPartNr}
        {enable-take-address=true, indirect-api=false, port-defined-argument-value{value=48, value-type=NvM_BlockIdType}, port=PS_Rte_NvmBlock_CmnMfgSrv_CcaSerlNr}
        {enable-take-address=true, indirect-api=false, port-defined-argument-value{value=48, value-type=NvM_BlockIdType}, port=PAdmin_Rte_NvmBlock_CmnMfgSrv_CcaSerlNr}
        {enable-take-address=true, indirect-api=false, port-defined-argument-value{value=47, value-type=NvM_BlockIdType}, port=PS_Rte_NvmBlock_CmnMfgSrv_DiRestore}
        {enable-take-address=true, indirect-api=false, port-defined-argument-value{value=47, value-type=NvM_BlockIdType}, port=PAdmin_Rte_NvmBlock_CmnMfgSrv_DiRestore}
        {enable-take-address=true, indirect-api=false, port-defined-argument-value{value=46, value-type=NvM_BlockIdType}, port=PS_Rte_NvmBlock_CmnMfgSrv_EpsSysSerlNr}
        {enable-take-address=true, indirect-api=false, port-defined-argument-value{value=46, value-type=NvM_BlockIdType}, port=PAdmin_Rte_NvmBlock_CmnMfgSrv_EpsSysSerlNr}
        {enable-take-address=true, indirect-api=false, port-defined-argument-value{value=45, value-type=NvM_BlockIdType}, port=PS_Rte_NvmBlock_CmnMfgSrv_IgnCntr}
        {enable-take-address=true, indirect-api=false, port-defined-argument-value{value=45, value-type=NvM_BlockIdType}, port=PAdmin_Rte_NvmBlock_CmnMfgSrv_IgnCntr}
        {enable-take-address=true, indirect-api=false, port-defined-argument-value{value=44, value-type=NvM_BlockIdType}, port=PS_Rte_NvmBlock_CmnMfgSrv_NxtrMfgEnaCntr}
        {enable-take-address=true, indirect-api=false, port-defined-argument-value{value=44, value-type=NvM_BlockIdType}, port=PAdmin_Rte_NvmBlock_CmnMfgSrv_NxtrMfgEnaCntr}
        {enable-take-address=true, indirect-api=false, port-defined-argument-value{value=43, value-type=NvM_BlockIdType}, port=PS_Rte_NvmBlock_CmnMfgSrv_MfgTmpBuf0}
        {enable-take-address=true, indirect-api=false, port-defined-argument-value{value=43, value-type=NvM_BlockIdType}, port=PAdmin_Rte_NvmBlock_CmnMfgSrv_MfgTmpBuf0}
        {enable-take-address=true, indirect-api=false, port-defined-argument-value{value=42, value-type=NvM_BlockIdType}, port=PS_Rte_NvmBlock_CmnMfgSrv_MfgTmpBuf1}
        {enable-take-address=true, indirect-api=false, port-defined-argument-value{value=42, value-type=NvM_BlockIdType}, port=PAdmin_Rte_NvmBlock_CmnMfgSrv_MfgTmpBuf1}
        {enable-take-address=true, indirect-api=false, port-defined-argument-value{value=41, value-type=NvM_BlockIdType}, port=PS_Rte_NvmBlock_CmnMfgSrv_MfgTmpBuf2}
        {enable-take-address=true, indirect-api=false, port-defined-argument-value{value=41, value-type=NvM_BlockIdType}, port=PAdmin_Rte_NvmBlock_CmnMfgSrv_MfgTmpBuf2}
        {enable-take-address=true, indirect-api=false, port-defined-argument-value{value=40, value-type=NvM_BlockIdType}, port=PS_Rte_NvmBlock_CmnMfgSrv_MfgTmpBuf3}
        {enable-take-address=true, indirect-api=false, port-defined-argument-value{value=40, value-type=NvM_BlockIdType}, port=PAdmin_Rte_NvmBlock_CmnMfgSrv_MfgTmpBuf3}
        {enable-take-address=true, indirect-api=false, port-defined-argument-value{value=39, value-type=NvM_BlockIdType}, port=PS_Rte_NvmBlock_CmnMfgSrv_MfgTmpBuf4}
        {enable-take-address=true, indirect-api=false, port-defined-argument-value{value=39, value-type=NvM_BlockIdType}, port=PAdmin_Rte_NvmBlock_CmnMfgSrv_MfgTmpBuf4}
        {enable-take-address=true, indirect-api=false, port-defined-argument-value{value=38, value-type=NvM_BlockIdType}, port=PS_Rte_NvmBlock_CmnMfgSrv_SeedKey}
        {enable-take-address=true, indirect-api=false, port-defined-argument-value{value=38, value-type=NvM_BlockIdType}, port=PAdmin_Rte_NvmBlock_CmnMfgSrv_SeedKey}
        {enable-take-address=true, indirect-api=false, port-defined-argument-value{value=37, value-type=NvM_BlockIdType}, port=PS_Rte_NvmBlock_PolarityCfg_PolarityCfgSaved}
        {enable-take-address=true, indirect-api=false, port-defined-argument-value{value=37, value-type=NvM_BlockIdType}, port=PAdmin_Rte_NvmBlock_PolarityCfg_PolarityCfgSaved}
        {enable-take-address=true, indirect-api=false, port-defined-argument-value{value=36, value-type=NvM_BlockIdType}, port=PS_Rte_NvmBlock_CDD_MotAgCmp_MotAgCmpMotAgBackEmf}
        {enable-take-address=true, indirect-api=false, port-defined-argument-value{value=36, value-type=NvM_BlockIdType}, port=PAdmin_Rte_NvmBlock_CDD_MotAgCmp_MotAgCmpMotAgBackEmf}
        {enable-take-address=true, indirect-api=false, port-defined-argument-value{value=35, value-type=NvM_BlockIdType}, port=PS_Rte_NvmBlock_CDD_HwTq4Meas_HwTq4Offs_MirrorBlock}
        {enable-take-address=true, indirect-api=false, port-defined-argument-value{value=35, value-type=NvM_BlockIdType}, port=PAdmin_Rte_NvmBlock_CDD_HwTq4Meas_HwTq4Offs_MirrorBlock}
        {enable-take-address=true, indirect-api=false, port-defined-argument-value{value=34, value-type=NvM_BlockIdType}, port=PS_Rte_NvmBlock_CDD_HwTq5Meas_HwTq5Offs_MirrorBlock}
        {enable-take-address=true, indirect-api=false, port-defined-argument-value{value=34, value-type=NvM_BlockIdType}, port=PAdmin_Rte_NvmBlock_CDD_HwTq5Meas_HwTq5Offs_MirrorBlock}
        {enable-take-address=true, indirect-api=false, port-defined-argument-value{value=33, value-type=NvM_BlockIdType}, port=PS_Rte_NvmBlock_CDD_HwTq4Meas_HwTq4Sca_MirrorBlock}
        {enable-take-address=true, indirect-api=false, port-defined-argument-value{value=33, value-type=NvM_BlockIdType}, port=PAdmin_Rte_NvmBlock_CDD_HwTq4Meas_HwTq4Sca_MirrorBlock}
        {enable-take-address=true, indirect-api=false, port-defined-argument-value{value=32, value-type=NvM_BlockIdType}, port=PS_Rte_NvmBlock_CDD_HwTq5Meas_HwTq5Sca_MirrorBlock}
        {enable-take-address=true, indirect-api=false, port-defined-argument-value{value=32, value-type=NvM_BlockIdType}, port=PAdmin_Rte_NvmBlock_CDD_HwTq5Meas_HwTq5Sca_MirrorBlock}
        {enable-take-address=true, indirect-api=false, port-defined-argument-value{value=31, value-type=NvM_BlockIdType}, port=PS_Rte_NvmBlock_HwTqCorrln_HwTqChACmnModCmpLpFilSt}
        {enable-take-address=true, indirect-api=false, port-defined-argument-value{value=31, value-type=NvM_BlockIdType}, port=PAdmin_Rte_NvmBlock_HwTqCorrln_HwTqChACmnModCmpLpFilSt}
        {enable-take-address=true, indirect-api=false, port-defined-argument-value{value=30, value-type=NvM_BlockIdType}, port=PS_Rte_NvmBlock_DutyCycThermProtn_FilStVal}
        {enable-take-address=true, indirect-api=false, port-defined-argument-value{value=30, value-type=NvM_BlockIdType}, port=PAdmin_Rte_NvmBlock_DutyCycThermProtn_FilStVal}
        {enable-take-address=true, indirect-api=false, port-defined-argument-value{value=29, value-type=NvM_BlockIdType}, port=PS_Rte_NvmBlock_MotTqCmdSca_MotTqScaFac}
        {enable-take-address=true, indirect-api=false, port-defined-argument-value{value=29, value-type=NvM_BlockIdType}, port=PAdmin_Rte_NvmBlock_MotTqCmdSca_MotTqScaFac}
        {enable-take-address=true, indirect-api=false, port-defined-argument-value{value=28, value-type=NvM_BlockIdType}, port=PS_Rte_NvmBlock_MotCtrlPrmEstimn_MotPrmNom}
        {enable-take-address=true, indirect-api=false, port-defined-argument-value{value=28, value-type=NvM_BlockIdType}, port=PAdmin_Rte_NvmBlock_MotCtrlPrmEstimn_MotPrmNom}
        {enable-take-address=true, indirect-api=false, port-defined-argument-value{value=27, value-type=NvM_BlockIdType}, port=PS_Rte_NvmBlock_Vin}
        {enable-take-address=true, indirect-api=false, port-defined-argument-value{value=27, value-type=NvM_BlockIdType}, port=PAdmin_Rte_NvmBlock_Vin}
        {enable-take-address=true, indirect-api=false, port-defined-argument-value{value=26, value-type=NvM_BlockIdType}, port=PS_Rte_NvmBlock_Omc}
        {enable-take-address=true, indirect-api=false, port-defined-argument-value{value=26, value-type=NvM_BlockIdType}, port=PAdmin_Rte_NvmBlock_Omc}
        {enable-take-address=true, indirect-api=false, port-defined-argument-value{value=25, value-type=NvM_BlockIdType}, port=PS_NVM_BLOCK_BOOT_PROG_COUNTER}
        {enable-take-address=true, indirect-api=false, port-defined-argument-value{value=25, value-type=NvM_BlockIdType}, port=PAdmin_NVM_BLOCK_BOOT_PROG_COUNTER}
        {enable-take-address=true, indirect-api=false, port-defined-argument-value{value=24, value-type=NvM_BlockIdType}, port=PS_NVM_BLOCK_BOOT_PROG_DATA}
        {enable-take-address=true, indirect-api=false, port-defined-argument-value{value=24, value-type=NvM_BlockIdType}, port=PAdmin_NVM_BLOCK_BOOT_PROG_DATA}
        {enable-take-address=true, indirect-api=false, port-defined-argument-value{value=23, value-type=NvM_BlockIdType}, port=PS_NVM_BLOCK_BOOT_SVK_HISTORY}
        {enable-take-address=true, indirect-api=false, port-defined-argument-value{value=23, value-type=NvM_BlockIdType}, port=PAdmin_NVM_BLOCK_BOOT_SVK_HISTORY}
        {enable-take-address=true, indirect-api=false, port-defined-argument-value{value=22, value-type=NvM_BlockIdType}, port=PS_NVM_BLOCK_DLOG_SVK_SYS_SUPP}
        {enable-take-address=true, indirect-api=false, port-defined-argument-value{value=22, value-type=NvM_BlockIdType}, port=PAdmin_NVM_BLOCK_DLOG_SVK_SYS_SUPP}
        {enable-take-address=true, indirect-api=false, port-defined-argument-value{value=21, value-type=NvM_BlockIdType}, port=PS_NVM_BLOCK_DLOG_SVK_PLANT}
        {enable-take-address=true, indirect-api=false, port-defined-argument-value{value=21, value-type=NvM_BlockIdType}, port=PAdmin_NVM_BLOCK_DLOG_SVK_PLANT}
        {enable-take-address=true, indirect-api=false, port-defined-argument-value{value=20, value-type=NvM_BlockIdType}, port=PS_Rte_NvmBlock_Darh_ErrorQueue}
        {enable-take-address=true, indirect-api=false, port-defined-argument-value{value=20, value-type=NvM_BlockIdType}, port=PAdmin_Rte_NvmBlock_Darh_ErrorQueue}
        {enable-take-address=true, indirect-api=false, port-defined-argument-value{value=17, value-type=NvM_BlockIdType}, port=PS_Rte_NvmBlock_CDD_VrfyCritReg_MCalReadVrfyCritRegFltInfo}
        {enable-take-address=true, indirect-api=false, port-defined-argument-value{value=17, value-type=NvM_BlockIdType}, port=PAdmin_Rte_NvmBlock_CDD_VrfyCritReg_MCalReadVrfyCritRegFltInfo}
        {enable-take-address=true, indirect-api=false, port-defined-argument-value{value=16, value-type=NvM_BlockIdType}, port=PS_Rte_NvmBlock_BmwHwAgArbnAndEotPosn_BmwVehCentrOffs}
        {enable-take-address=true, indirect-api=false, port-defined-argument-value{value=16, value-type=NvM_BlockIdType}, port=PAdmin_Rte_NvmBlock_BmwHwAgArbnAndEotPosn_BmwVehCentrOffs}
        {enable-take-address=true, indirect-api=false, port-defined-argument-value{value=15, value-type=NvM_BlockIdType}, port=PS_Rte_NvmBlock_LrndRackCentr_LrndRackCentr}
        {enable-take-address=true, indirect-api=false, port-defined-argument-value{value=15, value-type=NvM_BlockIdType}, port=PAdmin_Rte_NvmBlock_LrndRackCentr_LrndRackCentr}
        {enable-take-address=true, indirect-api=false, port-defined-argument-value{value=14, value-type=NvM_BlockIdType}, port=PS_Rte_NvmBlock_ExcpnHndlg_McuDiagcData}
        {enable-take-address=true, indirect-api=false, port-defined-argument-value{value=14, value-type=NvM_BlockIdType}, port=PAdmin_Rte_NvmBlock_ExcpnHndlg_McuDiagcData}
        {enable-take-address=true, indirect-api=false, port-defined-argument-value{value=13, value-type=NvM_BlockIdType}, port=PS_Rte_NvmBlock_TEstimn_TFilStVal}
        {enable-take-address=true, indirect-api=false, port-defined-argument-value{value=13, value-type=NvM_BlockIdType}, port=PAdmin_Rte_NvmBlock_TEstimn_TFilStVal}
        {enable-take-address=true, indirect-api=false, port-defined-argument-value{value=12, value-type=NvM_BlockIdType}, port=PS_NVM_BLOCK_DLOG_SVK_ENTRY}
        {enable-take-address=true, indirect-api=false, port-defined-argument-value{value=12, value-type=NvM_BlockIdType}, port=PAdmin_NVM_BLOCK_DLOG_SVK_ENTRY}
        {enable-take-address=true, indirect-api=false, port-defined-argument-value{value=11, value-type=NvM_BlockIdType}, port=PS_Rte_NvmBlock_Darh_DiagnoseMasterEnable}
        {enable-take-address=true, indirect-api=false, port-defined-argument-value{value=11, value-type=NvM_BlockIdType}, port=PAdmin_Rte_NvmBlock_Darh_DiagnoseMasterEnable}
        {enable-take-address=true, indirect-api=false, port-defined-argument-value{value=10, value-type=NvM_BlockIdType}, port=PS_Rte_NvmBlock_Coding_CodingData}
        {enable-take-address=true, indirect-api=false, port-defined-argument-value{value=10, value-type=NvM_BlockIdType}, port=PAdmin_Rte_NvmBlock_Coding_CodingData}
        {enable-take-address=true, indirect-api=false, port-defined-argument-value{value=9, value-type=NvM_BlockIdType}, port=PS_Rte_NvmBlock_BmwTunSetHndlr_BmwDesIninIdx}
        {enable-take-address=true, indirect-api=false, port-defined-argument-value{value=9, value-type=NvM_BlockIdType}, port=PAdmin_Rte_NvmBlock_BmwTunSetHndlr_BmwDesIninIdx}
        {enable-take-address=true, indirect-api=false, port-defined-argument-value{value=8, value-type=NvM_BlockIdType}, port=PS_Rte_NvmBlock_BmwTunSetHndlr_NvmBmwDesIninOptSetAIdx}
        {enable-take-address=true, indirect-api=false, port-defined-argument-value{value=8, value-type=NvM_BlockIdType}, port=PAdmin_Rte_NvmBlock_BmwTunSetHndlr_NvmBmwDesIninOptSetAIdx}
        {enable-take-address=true, indirect-api=false, port-defined-argument-value{value=7, value-type=NvM_BlockIdType}, port=PS_Rte_NvmBlock_BmwDiagcSrvHndlg_MilesKmEeprom}
        {enable-take-address=true, indirect-api=false, port-defined-argument-value{value=7, value-type=NvM_BlockIdType}, port=PAdmin_Rte_NvmBlock_BmwDiagcSrvHndlg_MilesKmEeprom}
        {enable-take-address=true, indirect-api=false, port-defined-argument-value{value=6, value-type=NvM_BlockIdType}, port=PS_Rte_NvmBlock_BmwDiagcSrvHndlg_ProgCntr}
        {enable-take-address=true, indirect-api=false, port-defined-argument-value{value=6, value-type=NvM_BlockIdType}, port=PAdmin_Rte_NvmBlock_BmwDiagcSrvHndlg_ProgCntr}
        {enable-take-address=true, indirect-api=false, port-defined-argument-value{value=5, value-type=NvM_BlockIdType}, port=PS_Rte_NvmBlock_BmwDiagcSrvHndlg_ProgCntrMaxVal}
        {enable-take-address=true, indirect-api=false, port-defined-argument-value{value=5, value-type=NvM_BlockIdType}, port=PAdmin_Rte_NvmBlock_BmwDiagcSrvHndlg_ProgCntrMaxVal}
        {enable-take-address=true, indirect-api=false, port-defined-argument-value{value=4, value-type=NvM_BlockIdType}, port=PS_Rte_NvmBlock_BmwDiagcSrvHndlg_TestStamp}
        {enable-take-address=true, indirect-api=false, port-defined-argument-value{value=4, value-type=NvM_BlockIdType}, port=PAdmin_Rte_NvmBlock_BmwDiagcSrvHndlg_TestStamp}
        {enable-take-address=true, indirect-api=false, port-defined-argument-value{value=3, value-type=NvM_BlockIdType}, port=PAdmin_Rte_NvmBlock_PullCmpActv_PullCmpLongTerm}
        {enable-take-address=true, indirect-api=false, port-defined-argument-value{value=3, value-type=NvM_BlockIdType}, port=PS_Rte_NvmBlock_PullCmpActv_PullCmpLongTerm}
      11 x runnable:
        NvM_MainFunction
          11 x sync call, all with timeout=0:
            OpServerCallNvM_MainFunction_JobFinished_NvM_RpNotifyJobEnd_Rte_NvmBlock_Vin: operation=NvM_RpNotifyJobEnd_Rte_NvmBlock_Vin.JobFinished
            OpServerCallNvM_MainFunction_InitBlock_NvM_RpNotifyInit_NVM_BLOCK_BOOT_PROG_COUNTER: operation=NvM_RpNotifyInit_NVM_BLOCK_BOOT_PROG_COUNTER.InitBlock
            OpServerCallNvM_MainFunction_JobFinished_NvM_RpNotifyJobEnd_NVM_BLOCK_BOOT_PROG_COUNTER: operation=NvM_RpNotifyJobEnd_NVM_BLOCK_BOOT_PROG_COUNTER.JobFinished
            OpServerCallNvM_MainFunction_JobFinished_NvM_RpNotifyJobEnd_NVM_BLOCK_BOOT_SVK_HISTORY: operation=NvM_RpNotifyJobEnd_NVM_BLOCK_BOOT_SVK_HISTORY.JobFinished
            OpServerCallNvM_MainFunction_InitBlock_NvM_RpNotifyInit_NVM_BLOCK_BOOT_SVK_HISTORY: operation=NvM_RpNotifyInit_NVM_BLOCK_BOOT_SVK_HISTORY.InitBlock
            OpServerCallNvM_MainFunction_InitBlock_NvM_RpNotifyInit_NVM_BLOCK_BOOT_PROG_DATA: operation=NvM_RpNotifyInit_NVM_BLOCK_BOOT_PROG_DATA.InitBlock
            OpServerCallNvM_MainFunction_JobFinished_NvM_RpNotifyJobEnd_NVM_BLOCK_BOOT_PROG_DATA: operation=NvM_RpNotifyJobEnd_NVM_BLOCK_BOOT_PROG_DATA.JobFinished
            OpServerCallNvM_MainFunction_JobFinished_NvM_RpNotifyJobEnd_Rte_NvmBlock_Omc: operation=NvM_RpNotifyJobEnd_Rte_NvmBlock_Omc.JobFinished
            OpServerCallNvM_MainFunction_JobFinished_NvM_RpNotifyJobEnd_NVM_BLOCK_DLOG_SVK_ENTRY: operation=NvM_RpNotifyJobEnd_NVM_BLOCK_DLOG_SVK_ENTRY.JobFinished
            OpServerCallNvM_MainFunction_JobFinished_NvM_RpNotifyJobEnd_Rte_NvmBlock_Darh_DiagnoseMasterEnable: operation=NvM_RpNotifyJobEnd_Rte_NvmBlock_Darh_DiagnoseMasterEnable.JobFinished
            OpServerCallNvM_MainFunction_JobFinished_NvM_RpNotifyJobEnd_Rte_NvmBlock_Coding_CodingData: operation=NvM_RpNotifyJobEnd_Rte_NvmBlock_Coding_CodingData.JobFinished
        GetErrorStatus: can-be-invoked-concurrently=true, symbol=NvM_GetErrorStatus
        SetRamBlockStatus: can-be-invoked-concurrently=true, symbol=NvM_SetRamBlockStatus
        ReadBlock: can-be-invoked-concurrently=true, symbol=NvM_ReadBlock
        WriteBlock: can-be-invoked-concurrently=true, symbol=NvM_WriteBlock
        InvalidateNvBlock: can-be-invoked-concurrently=true, symbol=NvM_InvalidateNvBlock
        EraseBlock: can-be-invoked-concurrently=true, symbol=NvM_EraseNvBlock
        SetBlockProtection: can-be-invoked-concurrently=true, symbol=NvM_SetBlockProtection
        RestoreBlockDefaults: can-be-invoked-concurrently=true, symbol=NvM_RestoreBlockDefaults
        SetDataIndex: can-be-invoked-concurrently=true, symbol=NvM_SetDataIndex
        GetDataIndex: can-be-invoked-concurrently=true, symbol=NvM_GetDataIndex
  swc implementation NvMImplementation: programming-language=C, behavior=NvMInternalBehavior
